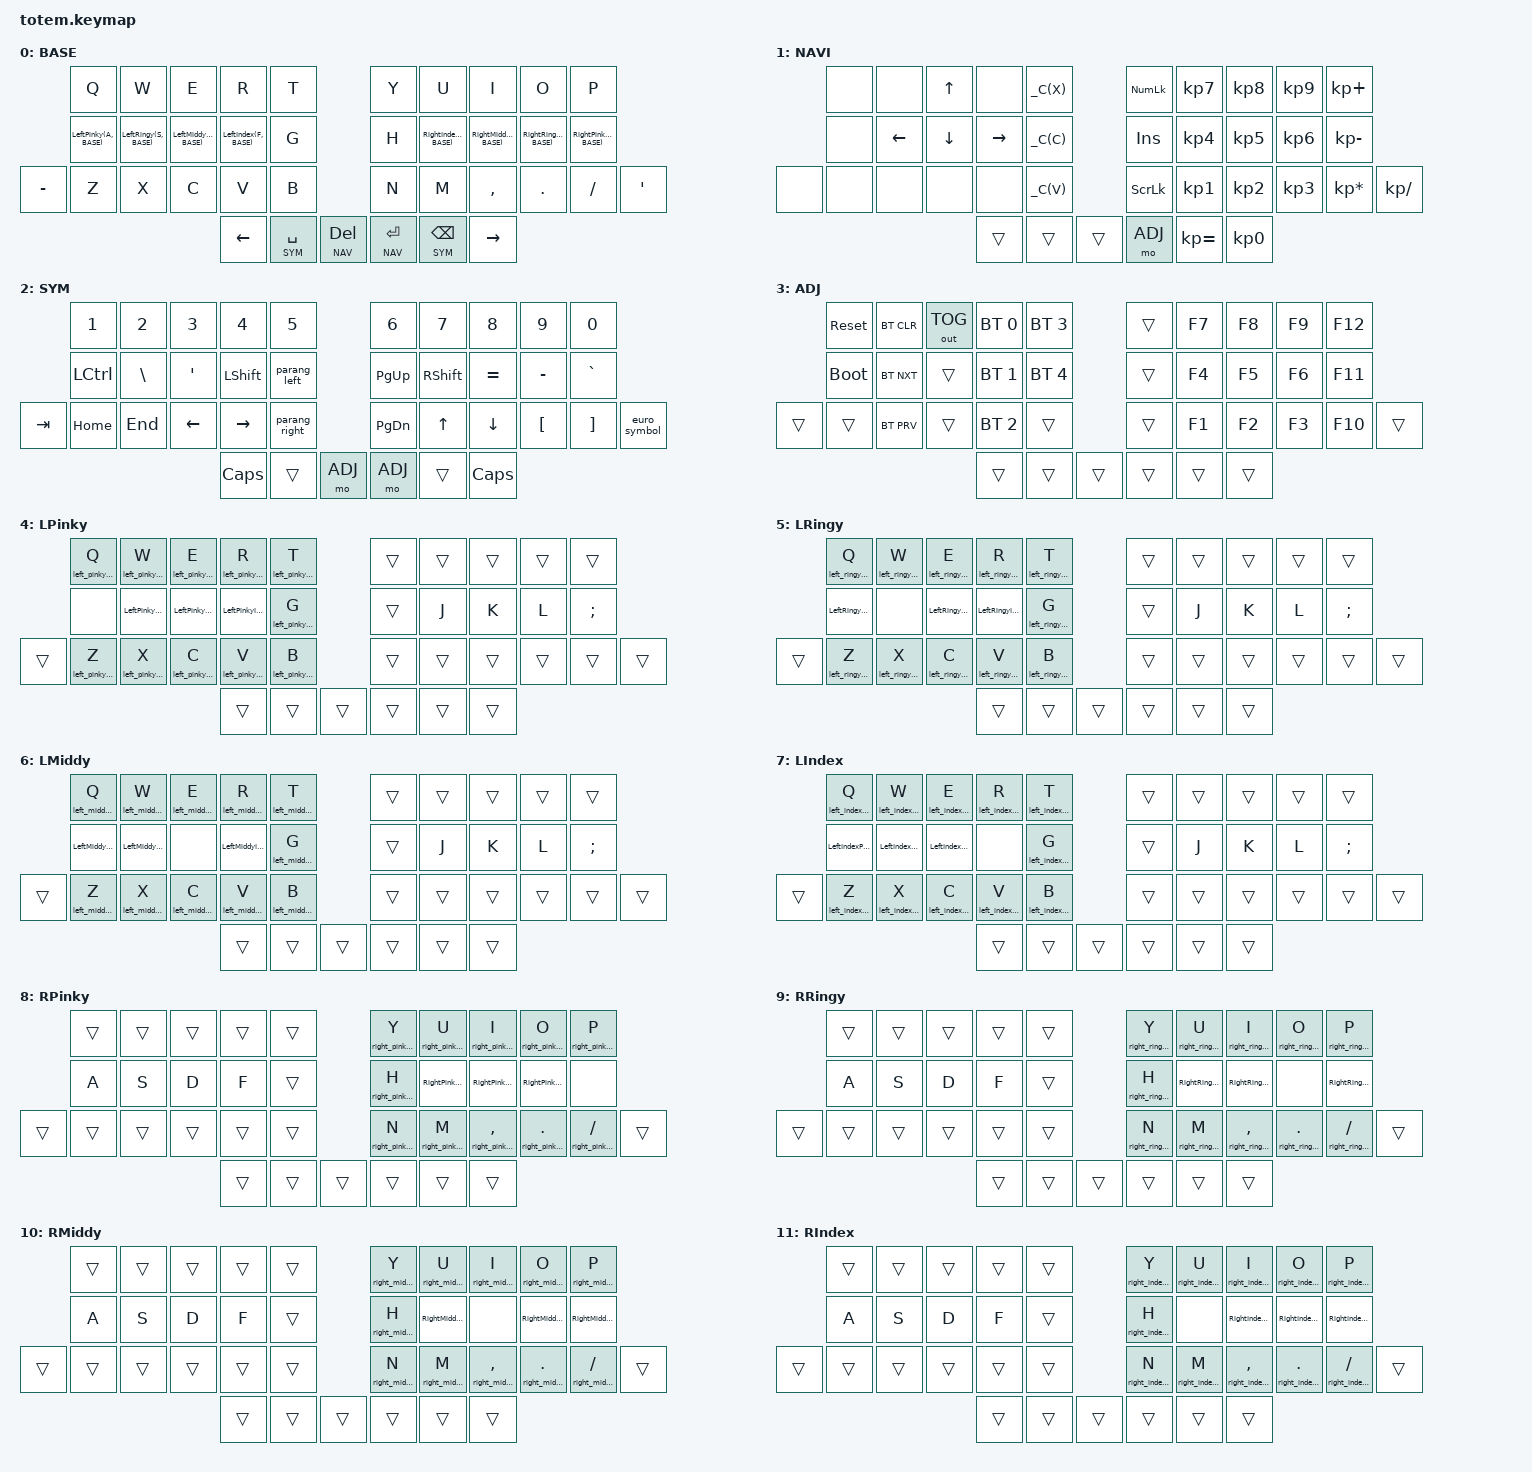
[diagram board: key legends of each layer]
//
//                                                        ▀▀▀▀▀     ▀▀▀▀▀          ▀▀█▀▀
//                                                        ▄▀▀▀▄  ▄  ▄▀▀▀▄  ▄  ▄▀▀▀▄  █  ▄▀▀▀▄
//                                                        █   █  █  █   █  █  █   █  █  █   █
//                                                         ▀▀▀   █   ▀▀▀   █   ▀▀▀   ▀   ▀▀▀
//                                                               █      ▄▄▄█▄▄▄    █   █
//                                                               ▀      █  █  █     █▄█
//                                                             ▀▀▀▀▀    █  █  █      ▀
//                                                                      ▀  ▀  ▀
//
// ▄▄▄▄▄▄▄▄▄▄▄▄▄▄▄▄▄▄▄▄▄▄▄▄▄▄▄▄▄▄▄▄▄▄▄▄▄▄▄▄▄▄▄▄▄▄▄▄▄▄▄▄▄▄▄▄▄▄▄▄▄▄▄▄▄▄▄▄▄▄▄▄▄▄▄▄▄▄▄▄▄▄▄▄▄▄▄▄▄▄▄▄▄▄▄▄▄▄▄▄▄▄▄▄▄▄▄▄▄▄▄▄▄▄▄▄▄▄▄▄▄▄▄▄▄▄▄▄▄▄▄▄▄▄▄▄▄▄▄▄▄▄▄▄▄▄▄▄▄
//
// TOTEM2 - Glove80-style bilateral home row mods with finger layers
// Based on: https://sunaku.github.io/home-row-mods.html
//

#include <behaviors.dtsi>
#include <dt-bindings/zmk/bt.h>
#include <dt-bindings/zmk/keys.h>
#include <dt-bindings/zmk/outputs.h>

// ▄▄▄▄▄▄▄▄▄▄▄▄▄▄▄▄▄▄▄▄▄▄▄▄▄▄▄▄▄▄▄▄▄▄▄▄▄▄▄▄▄▄▄▄▄▄▄▄▄▄▄▄▄▄▄▄▄▄▄▄▄▄▄▄▄▄▄▄▄▄▄▄▄▄▄▄▄▄▄▄▄▄▄▄▄▄▄▄▄▄▄▄▄▄▄▄▄▄▄▄▄▄▄▄▄▄▄▄▄▄▄▄▄▄▄▄▄▄▄▄▄▄▄▄▄▄▄▄▄▄▄▄▄▄▄▄▄▄▄▄▄▄▄▄▄▄▄▄▄
// LAYER DEFINITIONS
// ▄▄▄▄▄▄▄▄▄▄▄▄▄▄▄▄▄▄▄▄▄▄▄▄▄▄▄▄▄▄▄▄▄▄▄▄▄▄▄▄▄▄▄▄▄▄▄▄▄▄▄▄▄▄▄▄▄▄▄▄▄▄▄▄▄▄▄▄▄▄▄▄▄▄▄▄▄▄▄▄▄▄▄▄▄▄▄▄▄▄▄▄▄▄▄▄▄▄▄▄▄▄▄▄▄▄▄▄▄▄▄▄▄▄▄▄▄▄▄▄▄▄▄▄▄▄▄▄▄▄▄▄▄▄▄▄▄▄▄▄▄▄▄▄▄▄▄▄▄

#define BASE 0
#define NAV  1
#define SYM  2
#define ADJ  3
#define LAYER_LeftPinky 4
#define LAYER_LeftRingy 5
#define LAYER_LeftMiddy 6
#define LAYER_LeftIndex 7
#define LAYER_RightPinky 8
#define LAYER_RightRingy 9
#define LAYER_RightMiddy 10
#define LAYER_RightIndex 11

// ▄▄▄▄▄▄▄▄▄▄▄▄▄▄▄▄▄▄▄▄▄▄▄▄▄▄▄▄▄▄▄▄▄▄▄▄▄▄▄▄▄▄▄▄▄▄▄▄▄▄▄▄▄▄▄▄▄▄▄▄▄▄▄▄▄▄▄▄▄▄▄▄▄▄▄▄▄▄▄▄▄▄▄▄▄▄▄▄▄▄▄▄▄▄▄▄▄▄▄▄▄▄▄▄▄▄▄▄▄▄▄▄▄▄▄▄▄▄▄▄▄▄▄▄▄▄▄▄▄▄▄▄▄▄▄▄▄▄▄▄▄▄▄▄▄▄▄▄▄
// KEY POSITION DEFINITIONS (Totem 38-key layout)
// ▄▄▄▄▄▄▄▄▄▄▄▄▄▄▄▄▄▄▄▄▄▄▄▄▄▄▄▄▄▄▄▄▄▄▄▄▄▄▄▄▄▄▄▄▄▄▄▄▄▄▄▄▄▄▄▄▄▄▄▄▄▄▄▄▄▄▄▄▄▄▄▄▄▄▄▄▄▄▄▄▄▄▄▄▄▄▄▄▄▄▄▄▄▄▄▄▄▄▄▄▄▄▄▄▄▄▄▄▄▄▄▄▄▄▄▄▄▄▄▄▄▄▄▄▄▄▄▄▄▄▄▄▄▄▄▄▄▄▄▄▄▄▄▄▄▄▄▄▄
//
// Totem Layout (38 keys):
//     0   1   2   3   4       5   6   7   8   9
//    10  11  12  13  14      15  16  17  18  19
// 20 21  22  23  24  25      26  27  28  29  30  31
//            32  33  34      35  36  37
//

#define LEFT_HAND_KEYS      \
      0   1   2   3   4     \
     10  11  12  13  14     \
 20  21  22  23  24  25

#define RIGHT_HAND_KEYS     \
      5   6   7   8   9     \
     15  16  17  18  19     \
 26  27  28  29  30  31

#define THUMB_KEYS 32 33 34 35 36 37

// Home row key definitions for QWERTY
#define LEFT_PINKY_KEY   A
#define LEFT_RINGY_KEY   S
#define LEFT_MIDDY_KEY   D
#define LEFT_INDEX_KEY   F
#define RIGHT_INDEX_KEY  J
#define RIGHT_MIDDY_KEY  K
#define RIGHT_RINGY_KEY  L
#define RIGHT_PINKY_KEY  SEMI

// ▄▄▄▄▄▄▄▄▄▄▄▄▄▄▄▄▄▄▄▄▄▄▄▄▄▄▄▄▄▄▄▄▄▄▄▄▄▄▄▄▄▄▄▄▄▄▄▄▄▄▄▄▄▄▄▄▄▄▄▄▄▄▄▄▄▄▄▄▄▄▄▄▄▄▄▄▄▄▄▄▄▄▄▄▄▄▄▄▄▄▄▄▄▄▄▄▄▄▄▄▄▄▄▄▄▄▄▄▄▄▄▄▄▄▄▄▄▄▄▄▄▄▄▄▄▄▄▄▄▄▄▄▄▄▄▄▄▄▄▄▄▄▄▄▄▄▄▄▄
// OS-ADAPTIVE SHORTCUTS & MACROS
// ▄▄▄▄▄▄▄▄▄▄▄▄▄▄▄▄▄▄▄▄▄▄▄▄▄▄▄▄▄▄▄▄▄▄▄▄▄▄▄▄▄▄▄▄▄▄▄▄▄▄▄▄▄▄▄▄▄▄▄▄▄▄▄▄▄▄▄▄▄▄▄▄▄▄▄▄▄▄▄▄▄▄▄▄▄▄▄▄▄▄▄▄▄▄▄▄▄▄▄▄▄▄▄▄▄▄▄▄▄▄▄▄▄▄▄▄▄▄▄▄▄▄▄▄▄▄▄▄▄▄▄▄▄▄▄▄▄▄▄▄▄▄▄▄▄▄▄▄▄

// Uncomment for macOS:
// #define OPERATING_SYSTEM 'M'

#ifndef OPERATING_SYSTEM
#define OPERATING_SYSTEM 'W'
#endif

// Ctrl helper
#define _C(key) LC(key)

// OS-specific shortcuts
#if OPERATING_SYSTEM == 'M'
  #define _UNDO   LG(Z)
  #define _REDO   LG(LS(Z))
#else
  #define _UNDO   LC(Z)
  #define _REDO   LC(Y)
#endif

// Universal shortcuts
#define _CUT        _C(X)
#define _COPY       _C(C)
#define _PASTE      _C(V)
#define _FIND       _C(F)
#define _FIND_NEXT  _C(G)
#define _FIND_PREV  _C(LS(G))

// ▄▄▄▄▄▄▄▄▄▄▄▄▄▄▄▄▄▄▄▄▄▄▄▄▄▄▄▄▄▄▄▄▄▄▄▄▄▄▄▄▄▄▄▄▄▄▄▄▄▄▄▄▄▄▄▄▄▄▄▄▄▄▄▄▄▄▄▄▄▄▄▄▄▄▄▄▄▄▄▄▄▄▄▄▄▄▄▄▄▄▄▄▄▄▄▄▄▄▄▄▄▄▄▄▄▄▄▄▄▄▄▄▄▄▄▄▄▄▄▄▄▄▄▄▄▄▄▄▄▄▄▄▄▄▄▄▄▄▄▄▄▄▄▄▄▄▄▄▄
// HOME ROW MODS CONFIGURATION
// ▄▄▄▄▄▄▄▄▄▄▄▄▄▄▄▄▄▄▄▄▄▄▄▄▄▄▄▄▄▄▄▄▄▄▄▄▄▄▄▄▄▄▄▄▄▄▄▄▄▄▄▄▄▄▄▄▄▄▄▄▄▄▄▄▄▄▄▄▄▄▄▄▄▄▄▄▄▄▄▄▄▄▄▄▄▄▄▄▄▄▄▄▄▄▄▄▄▄▄▄▄▄▄▄▄▄▄▄▄▄▄▄▄▄▄▄▄▄▄▄▄▄▄▄▄▄▄▄▄▄▄▄▄▄▄▄▄▄▄▄▄▄▄▄▄▄▄▄▄

// Base timing (from glove80)
#ifndef TAPPING_RESOLUTION
#define TAPPING_RESOLUTION 150
#endif

// Holding times per finger
#ifndef HOMEY_HOLDING_TIME
#define HOMEY_HOLDING_TIME (TAPPING_RESOLUTION + 90)
#endif
#ifndef INDEX_HOLDING_TIME
#define INDEX_HOLDING_TIME (TAPPING_RESOLUTION - 30)  // 120ms - very fast for frequent Shift usage
#endif
#ifndef MIDDY_HOLDING_TIME
#define MIDDY_HOLDING_TIME (TAPPING_RESOLUTION + 60)
#endif
#ifndef RINGY_HOLDING_TIME
#define RINGY_HOLDING_TIME (TAPPING_RESOLUTION + 90)
#endif
#ifndef PINKY_HOLDING_TIME
#define PINKY_HOLDING_TIME (TAPPING_RESOLUTION + 130)
#endif

// Streak and repeat decay
#ifndef HOMEY_STREAK_DECAY
#define HOMEY_STREAK_DECAY TAPPING_RESOLUTION
#endif
#ifndef HOMEY_REPEAT_DECAY
#define HOMEY_REPEAT_DECAY (TAPPING_RESOLUTION + 150)
#endif
#ifndef INDEX_STREAK_DECAY
#define INDEX_STREAK_DECAY TAPPING_RESOLUTION
#endif
#ifndef INDEX_REPEAT_DECAY
#define INDEX_REPEAT_DECAY (TAPPING_RESOLUTION + 150)
#endif

// Holding types
#ifndef HOMEY_HOLDING_TYPE
#define HOMEY_HOLDING_TYPE "tap-preferred"
#endif
#ifndef INDEX_HOLDING_TYPE
#define INDEX_HOLDING_TYPE "tap-preferred"
#endif

// Chord timing (faster than single-finger)
#ifndef CHORD_HOLDING_TIME
#define CHORD_HOLDING_TIME TAPPING_RESOLUTION
#endif
#ifndef CHORD_STREAK_DECAY
#define CHORD_STREAK_DECAY HOMEY_STREAK_DECAY
#endif
#ifndef CHORD_REPEAT_DECAY
#define CHORD_REPEAT_DECAY HOMEY_REPEAT_DECAY
#endif

// Per-finger settings - LEFT HAND
#ifndef LEFT_PINKY_HOLDING_TIME
#define LEFT_PINKY_HOLDING_TIME PINKY_HOLDING_TIME
#endif
#ifndef LEFT_PINKY_STREAK_DECAY
#define LEFT_PINKY_STREAK_DECAY HOMEY_STREAK_DECAY
#endif
#ifndef LEFT_PINKY_REPEAT_DECAY
#define LEFT_PINKY_REPEAT_DECAY HOMEY_REPEAT_DECAY
#endif
#ifndef LEFT_PINKY_HOLDING_TYPE
#define LEFT_PINKY_HOLDING_TYPE HOMEY_HOLDING_TYPE
#endif

#ifndef LEFT_RINGY_HOLDING_TIME
#define LEFT_RINGY_HOLDING_TIME RINGY_HOLDING_TIME
#endif
#ifndef LEFT_RINGY_STREAK_DECAY
#define LEFT_RINGY_STREAK_DECAY HOMEY_STREAK_DECAY
#endif
#ifndef LEFT_RINGY_REPEAT_DECAY
#define LEFT_RINGY_REPEAT_DECAY HOMEY_REPEAT_DECAY
#endif
#ifndef LEFT_RINGY_HOLDING_TYPE
#define LEFT_RINGY_HOLDING_TYPE HOMEY_HOLDING_TYPE
#endif

#ifndef LEFT_MIDDY_HOLDING_TIME
#define LEFT_MIDDY_HOLDING_TIME MIDDY_HOLDING_TIME
#endif
#ifndef LEFT_MIDDY_STREAK_DECAY
#define LEFT_MIDDY_STREAK_DECAY HOMEY_STREAK_DECAY
#endif
#ifndef LEFT_MIDDY_REPEAT_DECAY
#define LEFT_MIDDY_REPEAT_DECAY HOMEY_REPEAT_DECAY
#endif
#ifndef LEFT_MIDDY_HOLDING_TYPE
#define LEFT_MIDDY_HOLDING_TYPE HOMEY_HOLDING_TYPE
#endif

#ifndef LEFT_INDEX_HOLDING_TIME
#define LEFT_INDEX_HOLDING_TIME INDEX_HOLDING_TIME
#endif
#ifndef LEFT_INDEX_STREAK_DECAY
#define LEFT_INDEX_STREAK_DECAY INDEX_STREAK_DECAY
#endif
#ifndef LEFT_INDEX_REPEAT_DECAY
#define LEFT_INDEX_REPEAT_DECAY INDEX_REPEAT_DECAY
#endif
#ifndef LEFT_INDEX_HOLDING_TYPE
#define LEFT_INDEX_HOLDING_TYPE INDEX_HOLDING_TYPE
#endif

// Per-finger settings - RIGHT HAND
#ifndef RIGHT_PINKY_HOLDING_TIME
#define RIGHT_PINKY_HOLDING_TIME PINKY_HOLDING_TIME
#endif
#ifndef RIGHT_PINKY_STREAK_DECAY
#define RIGHT_PINKY_STREAK_DECAY HOMEY_STREAK_DECAY
#endif
#ifndef RIGHT_PINKY_REPEAT_DECAY
#define RIGHT_PINKY_REPEAT_DECAY HOMEY_REPEAT_DECAY
#endif
#ifndef RIGHT_PINKY_HOLDING_TYPE
#define RIGHT_PINKY_HOLDING_TYPE HOMEY_HOLDING_TYPE
#endif

#ifndef RIGHT_RINGY_HOLDING_TIME
#define RIGHT_RINGY_HOLDING_TIME RINGY_HOLDING_TIME
#endif
#ifndef RIGHT_RINGY_STREAK_DECAY
#define RIGHT_RINGY_STREAK_DECAY HOMEY_STREAK_DECAY
#endif
#ifndef RIGHT_RINGY_REPEAT_DECAY
#define RIGHT_RINGY_REPEAT_DECAY HOMEY_REPEAT_DECAY
#endif
#ifndef RIGHT_RINGY_HOLDING_TYPE
#define RIGHT_RINGY_HOLDING_TYPE HOMEY_HOLDING_TYPE
#endif

#ifndef RIGHT_MIDDY_HOLDING_TIME
#define RIGHT_MIDDY_HOLDING_TIME MIDDY_HOLDING_TIME
#endif
#ifndef RIGHT_MIDDY_STREAK_DECAY
#define RIGHT_MIDDY_STREAK_DECAY HOMEY_STREAK_DECAY
#endif
#ifndef RIGHT_MIDDY_REPEAT_DECAY
#define RIGHT_MIDDY_REPEAT_DECAY HOMEY_REPEAT_DECAY
#endif
#ifndef RIGHT_MIDDY_HOLDING_TYPE
#define RIGHT_MIDDY_HOLDING_TYPE HOMEY_HOLDING_TYPE
#endif

#ifndef RIGHT_INDEX_HOLDING_TIME
#define RIGHT_INDEX_HOLDING_TIME INDEX_HOLDING_TIME
#endif
#ifndef RIGHT_INDEX_STREAK_DECAY
#define RIGHT_INDEX_STREAK_DECAY INDEX_STREAK_DECAY
#endif
#ifndef RIGHT_INDEX_REPEAT_DECAY
#define RIGHT_INDEX_REPEAT_DECAY INDEX_REPEAT_DECAY
#endif
#ifndef RIGHT_INDEX_HOLDING_TYPE
#define RIGHT_INDEX_HOLDING_TYPE INDEX_HOLDING_TYPE
#endif

// Chord timing per finger - LEFT HAND
#ifndef LEFT_PINKY_CHORD_HOLDING_TIME
#define LEFT_PINKY_CHORD_HOLDING_TIME CHORD_HOLDING_TIME
#endif
#ifndef LEFT_PINKY_CHORD_STREAK_DECAY
#define LEFT_PINKY_CHORD_STREAK_DECAY CHORD_STREAK_DECAY
#endif
#ifndef LEFT_PINKY_CHORD_REPEAT_DECAY
#define LEFT_PINKY_CHORD_REPEAT_DECAY CHORD_REPEAT_DECAY
#endif

#ifndef LEFT_RINGY_CHORD_HOLDING_TIME
#define LEFT_RINGY_CHORD_HOLDING_TIME CHORD_HOLDING_TIME
#endif
#ifndef LEFT_RINGY_CHORD_STREAK_DECAY
#define LEFT_RINGY_CHORD_STREAK_DECAY CHORD_STREAK_DECAY
#endif
#ifndef LEFT_RINGY_CHORD_REPEAT_DECAY
#define LEFT_RINGY_CHORD_REPEAT_DECAY CHORD_REPEAT_DECAY
#endif

#ifndef LEFT_MIDDY_CHORD_HOLDING_TIME
#define LEFT_MIDDY_CHORD_HOLDING_TIME CHORD_HOLDING_TIME
#endif
#ifndef LEFT_MIDDY_CHORD_STREAK_DECAY
#define LEFT_MIDDY_CHORD_STREAK_DECAY CHORD_STREAK_DECAY
#endif
#ifndef LEFT_MIDDY_CHORD_REPEAT_DECAY
#define LEFT_MIDDY_CHORD_REPEAT_DECAY CHORD_REPEAT_DECAY
#endif

#ifndef LEFT_INDEX_CHORD_HOLDING_TIME
#define LEFT_INDEX_CHORD_HOLDING_TIME CHORD_HOLDING_TIME
#endif
#ifndef LEFT_INDEX_CHORD_STREAK_DECAY
#define LEFT_INDEX_CHORD_STREAK_DECAY CHORD_STREAK_DECAY
#endif
#ifndef LEFT_INDEX_CHORD_REPEAT_DECAY
#define LEFT_INDEX_CHORD_REPEAT_DECAY CHORD_REPEAT_DECAY
#endif

// Chord timing per finger - RIGHT HAND
#ifndef RIGHT_PINKY_CHORD_HOLDING_TIME
#define RIGHT_PINKY_CHORD_HOLDING_TIME CHORD_HOLDING_TIME
#endif
#ifndef RIGHT_PINKY_CHORD_STREAK_DECAY
#define RIGHT_PINKY_CHORD_STREAK_DECAY CHORD_STREAK_DECAY
#endif
#ifndef RIGHT_PINKY_CHORD_REPEAT_DECAY
#define RIGHT_PINKY_CHORD_REPEAT_DECAY CHORD_REPEAT_DECAY
#endif

#ifndef RIGHT_RINGY_CHORD_HOLDING_TIME
#define RIGHT_RINGY_CHORD_HOLDING_TIME CHORD_HOLDING_TIME
#endif
#ifndef RIGHT_RINGY_CHORD_STREAK_DECAY
#define RIGHT_RINGY_CHORD_STREAK_DECAY CHORD_STREAK_DECAY
#endif
#ifndef RIGHT_RINGY_CHORD_REPEAT_DECAY
#define RIGHT_RINGY_CHORD_REPEAT_DECAY CHORD_REPEAT_DECAY
#endif

#ifndef RIGHT_MIDDY_CHORD_HOLDING_TIME
#define RIGHT_MIDDY_CHORD_HOLDING_TIME CHORD_HOLDING_TIME
#endif
#ifndef RIGHT_MIDDY_CHORD_STREAK_DECAY
#define RIGHT_MIDDY_CHORD_STREAK_DECAY CHORD_STREAK_DECAY
#endif
#ifndef RIGHT_MIDDY_CHORD_REPEAT_DECAY
#define RIGHT_MIDDY_CHORD_REPEAT_DECAY CHORD_REPEAT_DECAY
#endif

#ifndef RIGHT_INDEX_CHORD_HOLDING_TIME
#define RIGHT_INDEX_CHORD_HOLDING_TIME CHORD_HOLDING_TIME
#endif
#ifndef RIGHT_INDEX_CHORD_STREAK_DECAY
#define RIGHT_INDEX_CHORD_STREAK_DECAY CHORD_STREAK_DECAY
#endif
#ifndef RIGHT_INDEX_CHORD_REPEAT_DECAY
#define RIGHT_INDEX_CHORD_REPEAT_DECAY CHORD_REPEAT_DECAY
#endif

// Modifier assignments (GACS order)
#ifndef PINKY_FINGER_MOD
#define PINKY_FINGER_MOD LGUI
#endif
#ifndef RINGY_FINGER_MOD
#define RINGY_FINGER_MOD LALT
#endif
#ifndef MIDDY_FINGER_MOD
#define MIDDY_FINGER_MOD LCTL
#endif
#ifndef INDEX_FINGER_MOD
#define INDEX_FINGER_MOD LSFT
#endif

#ifndef LEFT_PINKY_MOD
#define LEFT_PINKY_MOD PINKY_FINGER_MOD
#endif
#ifndef RIGHT_PINKY_MOD
#define RIGHT_PINKY_MOD PINKY_FINGER_MOD
#endif
#ifndef LEFT_RINGY_MOD
#define LEFT_RINGY_MOD RINGY_FINGER_MOD
#endif
#ifndef RIGHT_RINGY_MOD
#define RIGHT_RINGY_MOD RINGY_FINGER_MOD
#endif
#ifndef LEFT_MIDDY_MOD
#define LEFT_MIDDY_MOD MIDDY_FINGER_MOD
#endif
#ifndef RIGHT_MIDDY_MOD
#define RIGHT_MIDDY_MOD MIDDY_FINGER_MOD
#endif
#ifndef LEFT_INDEX_MOD
#define LEFT_INDEX_MOD INDEX_FINGER_MOD
#endif
#ifndef RIGHT_INDEX_MOD
#define RIGHT_INDEX_MOD INDEX_FINGER_MOD
#endif

/ {
    behaviors {

// ▄▄▄▄▄▄▄▄▄▄▄▄▄▄▄▄▄▄▄▄▄▄▄▄▄▄▄▄▄▄▄▄▄▄▄▄▄▄▄▄▄▄▄▄▄▄▄▄▄▄▄▄▄▄▄▄▄▄▄▄▄▄▄▄▄▄▄▄▄▄▄▄▄▄▄▄▄▄▄▄▄▄▄▄▄▄▄▄▄▄▄▄▄▄▄▄▄▄▄▄▄▄▄▄▄▄▄▄▄▄▄▄▄▄▄▄▄▄▄▄▄▄▄▄▄▄▄▄▄▄▄▄▄▄▄▄▄▄▄▄▄▄▄▄▄▄▄▄▄
// TEXT SELECTION BEHAVIORS
// ▄▄▄▄▄▄▄▄▄▄▄▄▄▄▄▄▄▄▄▄▄▄▄▄▄▄▄▄▄▄▄▄▄▄▄▄▄▄▄▄▄▄▄▄▄▄▄▄▄▄▄▄▄▄▄▄▄▄▄▄▄▄▄▄▄▄▄▄▄▄▄▄▄▄▄▄▄▄▄▄▄▄▄▄▄▄▄▄▄▄▄▄▄▄▄▄▄▄▄▄▄▄▄▄▄▄▄▄▄▄▄▄▄▄▄▄▄▄▄▄▄▄▄▄▄▄▄▄▄▄▄▄▄▄▄▄▄▄▄▄▄▄▄▄▄▄▄▄▄

        // Select all macro
        #define select_all kp _C(A)

        // Select word (with direction based on shift)
        select_word_right: select_word_right {
            compatible = "zmk,behavior-macro";
            #binding-cells = <0>;
            wait-ms = <10>;
            tap-ms = <10>;
            bindings = <&kp LC(RIGHT) &kp LS(LC(RIGHT))>;
        };
        select_word_left: select_word_left {
            compatible = "zmk,behavior-macro";
            #binding-cells = <0>;
            wait-ms = <10>;
            tap-ms = <10>;
            bindings = <&kp LC(LEFT) &kp LS(LC(LEFT))>;
        };
        select_word: select_word {
            compatible = "zmk,behavior-mod-morph";
            #binding-cells = <0>;
            bindings = <&select_word_right>, <&select_word_left>;
            mods = <(MOD_LSFT|MOD_RSFT)>;
        };

        // Extend word (extend selection by one word)
        extend_word_right: extend_word_right {
            compatible = "zmk,behavior-macro";
            #binding-cells = <0>;
            wait-ms = <10>;
            tap-ms = <10>;
            bindings = <&kp LS(LC(RIGHT))>;
        };
        extend_word_left: extend_word_left {
            compatible = "zmk,behavior-macro";
            #binding-cells = <0>;
            wait-ms = <10>;
            tap-ms = <10>;
            bindings = <&kp LS(LC(LEFT))>;
        };
        extend_word: extend_word {
            compatible = "zmk,behavior-mod-morph";
            #binding-cells = <0>;
            bindings = <&extend_word_right>, <&extend_word_left>;
            mods = <(MOD_LSFT|MOD_RSFT)>;
        };

        // Parenthesis/angle bracket morphs
        parang_left: parang_left {
            compatible = "zmk,behavior-mod-morph";
            label = "PARANG_LEFT";
            #binding-cells = <0>;
            bindings = <&kp LPAR>, <&kp LT>;
            mods = <(MOD_LSFT|MOD_RSFT)>;
        };
        parang_right: parang_right {
            compatible = "zmk,behavior-mod-morph";
            label = "PARANG_RIGHT";
            #binding-cells = <0>;
            bindings = <&kp RPAR>, <&kp GT>;
            mods = <(MOD_LSFT|MOD_RSFT)>;
        };

        // Euro symbol macro (Windows: Alt+0128)
        euro_symbol: euro_symbol {
            compatible = "zmk,behavior-macro";
            #binding-cells = <0>;
            wait-ms = <10>;
            tap-ms = <10>;
            bindings = <&macro_press &kp LALT>
                     , <&macro_tap &kp KP_N0 &kp KP_N1 &kp KP_N2 &kp KP_N8>
                     , <&macro_release &kp LALT>;
        };

// ▄▄▄▄▄▄▄▄▄▄▄▄▄▄▄▄▄▄▄▄▄▄▄▄▄▄▄▄▄▄▄▄▄▄▄▄▄▄▄▄▄▄▄▄▄▄▄▄▄▄▄▄▄▄▄▄▄▄▄▄▄▄▄▄▄▄▄▄▄▄▄▄▄▄▄▄▄▄▄▄▄▄▄▄▄▄▄▄▄▄▄▄▄▄▄▄▄▄▄▄▄▄▄▄▄▄▄▄▄▄▄▄▄▄▄▄▄▄▄▄▄▄▄▄▄▄▄▄▄▄▄▄▄▄▄▄▄▄▄▄▄▄▄▄▄▄▄▄▄
// THUMB LAYER-TAP BEHAVIORS WITH AUTO-REPEAT
// ▄▄▄▄▄▄▄▄▄▄▄▄▄▄▄▄▄▄▄▄▄▄▄▄▄▄▄▄▄▄▄▄▄▄▄▄▄▄▄▄▄▄▄▄▄▄▄▄▄▄▄▄▄▄▄▄▄▄▄▄▄▄▄▄▄▄▄▄▄▄▄▄▄▄▄▄▄▄▄▄▄▄▄▄▄▄▄▄▄▄▄▄▄▄▄▄▄▄▄▄▄▄▄▄▄▄▄▄▄▄▄▄▄▄▄▄▄▄▄▄▄▄▄▄▄▄▄▄▄▄▄▄▄▄▄▄▄▄▄▄▄▄▄▄▄▄▄▄▄

        // Thumb layer-tap with auto-repeat: tap for key, hold for layer, tap-tap-hold for auto-repeat
        lt_space_sym: lt_space_sym {
            compatible = "zmk,behavior-hold-tap";
            label = "LT_SPACE_SYM";
            #binding-cells = <2>;
            flavor = "balanced";
            tapping-term-ms = <200>;
            quick-tap-ms = <200>;  // Enable "tap then hold" for auto-repeat
            bindings = <&mo>, <&kp>;
        };

        lt_bspc_sym: lt_bspc_sym {
            compatible = "zmk,behavior-hold-tap";
            label = "LT_BSPC_SYM";
            #binding-cells = <2>;
            flavor = "balanced";
            tapping-term-ms = <200>;
            quick-tap-ms = <200>;
            bindings = <&mo>, <&kp>;
        };

        lt_del_nav: lt_del_nav {
            compatible = "zmk,behavior-hold-tap";
            label = "LT_DEL_NAV";
            #binding-cells = <2>;
            flavor = "balanced";
            tapping-term-ms = <200>;
            quick-tap-ms = <200>;
            bindings = <&mo>, <&kp>;
        };

        lt_ret_nav: lt_ret_nav {
            compatible = "zmk,behavior-hold-tap";
            label = "LT_RET_NAV";
            #binding-cells = <2>;
            flavor = "balanced";
            tapping-term-ms = <200>;
            quick-tap-ms = <200>;
            bindings = <&mo>, <&kp>;
        };

// ▄▄▄▄▄▄▄▄▄▄▄▄▄▄▄▄▄▄▄▄▄▄▄▄▄▄▄▄▄▄▄▄▄▄▄▄▄▄▄▄▄▄▄▄▄▄▄▄▄▄▄▄▄▄▄▄▄▄▄▄▄▄▄▄▄▄▄▄▄▄▄▄▄▄▄▄▄▄▄▄▄▄▄▄▄▄▄▄▄▄▄▄▄▄▄▄▄▄▄▄▄▄▄▄▄▄▄▄▄▄▄▄▄▄▄▄▄▄▄▄▄▄▄▄▄▄▄▄▄▄▄▄▄▄▄▄▄▄▄▄▄▄▄▄▄▄▄▄▄
// LEFT PINKY BEHAVIORS
// ▄▄▄▄▄▄▄▄▄▄▄▄▄▄▄▄▄▄▄▄▄▄▄▄▄▄▄▄▄▄▄▄▄▄▄▄▄▄▄▄▄▄▄▄▄▄▄▄▄▄▄▄▄▄▄▄▄▄▄▄▄▄▄▄▄▄▄▄▄▄▄▄▄▄▄▄▄▄▄▄▄▄▄▄▄▄▄▄▄▄▄▄▄▄▄▄▄▄▄▄▄▄▄▄▄▄▄▄▄▄▄▄▄▄▄▄▄▄▄▄▄▄▄▄▄▄▄▄▄▄▄▄▄▄▄▄▄▄▄▄▄▄▄▄▄▄▄▄▄

        left_pinky: homey_left_pinky {
            compatible = "zmk,behavior-hold-tap";
            flavor = LEFT_PINKY_HOLDING_TYPE;
            hold-trigger-key-positions = <RIGHT_HAND_KEYS THUMB_KEYS>;
            hold-trigger-on-release;
            tapping-term-ms = <LEFT_PINKY_HOLDING_TIME>;
            quick-tap-ms = <LEFT_PINKY_REPEAT_DECAY>;
            require-prior-idle-ms = <LEFT_PINKY_STREAK_DECAY>;
            #binding-cells = <2>;
            bindings = <&kp>, <&kp>;
        };

        left_pinky_bilateral: homey_left_pinky_bilateral {
            compatible = "zmk,behavior-hold-tap";
            flavor = LEFT_PINKY_HOLDING_TYPE;
            hold-trigger-key-positions = <RIGHT_HAND_KEYS THUMB_KEYS>;
            hold-trigger-on-release;
            tapping-term-ms = <LEFT_PINKY_HOLDING_TIME>;
            quick-tap-ms = <LEFT_PINKY_REPEAT_DECAY>;
            require-prior-idle-ms = <LEFT_PINKY_STREAK_DECAY>;
            #binding-cells = <2>;
            bindings = <&left_pinky_hold>, <&kp>;
        };

        left_pinky_hold: homey_left_pinky_hold {
            compatible = "zmk,behavior-macro-one-param";
            wait-ms = <0>;
            tap-ms = <0>;
            #binding-cells = <1>;
            bindings
                = <&macro_param_1to1>
                , <&macro_press &kp MACRO_PLACEHOLDER>
                , <&macro_press &mo LAYER_LeftPinky>
                , <&macro_pause_for_release>
                , <&macro_param_1to1>
                , <&macro_release &kp MACRO_PLACEHOLDER>
                , <&macro_release &mo LAYER_LeftPinky>
                ;
        };

        left_pinky_tap: homey_left_pinky_tap {
            compatible = "zmk,behavior-macro-one-param";
            wait-ms = <0>;
            tap-ms = <0>;
            #binding-cells = <1>;
            bindings
                = <&macro_release
                    &kp LSFT &kp RSFT
                    &kp LALT &kp RALT
                    &kp LCTL &kp RCTL
                    &kp LGUI &kp RGUI>
                , <&macro_tap &kp LEFT_PINKY_KEY>
                , <&macro_param_1to1>
                , <&macro_tap &kp MACRO_PLACEHOLDER>
                ;
        };

        #define LeftPinky(key, layer_index) LeftPinky_unroll(layer_index) (key)
        #define LeftPinky_unroll(layer_index) LeftPinky_concat(LeftPinky_layer, layer_index)
        #define LeftPinky_concat(prefix, layer_index) prefix ## layer_index
        #define LeftPinky_layer0(key) left_pinky_bilateral LEFT_PINKY_MOD key
        #define LeftPinky_layer1(key) left_pinky LEFT_PINKY_MOD key
        #define LeftPinky_layer2(key) left_pinky LEFT_PINKY_MOD key
        #define LeftPinky_layer3(key) left_pinky LEFT_PINKY_MOD key

// ▄▄▄▄▄▄▄▄▄▄▄▄▄▄▄▄▄▄▄▄▄▄▄▄▄▄▄▄▄▄▄▄▄▄▄▄▄▄▄▄▄▄▄▄▄▄▄▄▄▄▄▄▄▄▄▄▄▄▄▄▄▄▄▄▄▄▄▄▄▄▄▄▄▄▄▄▄▄▄▄▄▄▄▄▄▄▄▄▄▄▄▄▄▄▄▄▄▄▄▄▄▄▄▄▄▄▄▄▄▄▄▄▄▄▄▄▄▄▄▄▄▄▄▄▄▄▄▄▄▄▄▄▄▄▄▄▄▄▄▄▄▄▄▄▄▄▄▄▄
// LEFT RINGY BEHAVIORS
// ▄▄▄▄▄▄▄▄▄▄▄▄▄▄▄▄▄▄▄▄▄▄▄▄▄▄▄▄▄▄▄▄▄▄▄▄▄▄▄▄▄▄▄▄▄▄▄▄▄▄▄▄▄▄▄▄▄▄▄▄▄▄▄▄▄▄▄▄▄▄▄▄▄▄▄▄▄▄▄▄▄▄▄▄▄▄▄▄▄▄▄▄▄▄▄▄▄▄▄▄▄▄▄▄▄▄▄▄▄▄▄▄▄▄▄▄▄▄▄▄▄▄▄▄▄▄▄▄▄▄▄▄▄▄▄▄▄▄▄▄▄▄▄▄▄▄▄▄▄

        left_ringy: homey_left_ringy {
            compatible = "zmk,behavior-hold-tap";
            flavor = LEFT_RINGY_HOLDING_TYPE;
            hold-trigger-key-positions = <RIGHT_HAND_KEYS THUMB_KEYS>;
            hold-trigger-on-release;
            tapping-term-ms = <LEFT_RINGY_HOLDING_TIME>;
            quick-tap-ms = <LEFT_RINGY_REPEAT_DECAY>;
            require-prior-idle-ms = <LEFT_RINGY_STREAK_DECAY>;
            #binding-cells = <2>;
            bindings = <&kp>, <&kp>;
        };

        left_ringy_bilateral: homey_left_ringy_bilateral {
            compatible = "zmk,behavior-hold-tap";
            flavor = LEFT_RINGY_HOLDING_TYPE;
            hold-trigger-key-positions = <RIGHT_HAND_KEYS THUMB_KEYS>;
            hold-trigger-on-release;
            tapping-term-ms = <LEFT_RINGY_HOLDING_TIME>;
            quick-tap-ms = <LEFT_RINGY_REPEAT_DECAY>;
            require-prior-idle-ms = <LEFT_RINGY_STREAK_DECAY>;
            #binding-cells = <2>;
            bindings = <&left_ringy_hold>, <&kp>;
        };

        left_ringy_hold: homey_left_ringy_hold {
            compatible = "zmk,behavior-macro-one-param";
            wait-ms = <0>;
            tap-ms = <0>;
            #binding-cells = <1>;
            bindings
                = <&macro_param_1to1>
                , <&macro_press &kp MACRO_PLACEHOLDER>
                , <&macro_press &mo LAYER_LeftRingy>
                , <&macro_pause_for_release>
                , <&macro_param_1to1>
                , <&macro_release &kp MACRO_PLACEHOLDER>
                , <&macro_release &mo LAYER_LeftRingy>
                ;
        };

        left_ringy_tap: homey_left_ringy_tap {
            compatible = "zmk,behavior-macro-one-param";
            wait-ms = <0>;
            tap-ms = <0>;
            #binding-cells = <1>;
            bindings
                = <&macro_release
                    &kp LSFT &kp RSFT
                    &kp LALT &kp RALT
                    &kp LCTL &kp RCTL
                    &kp LGUI &kp RGUI>
                , <&macro_tap &kp LEFT_RINGY_KEY>
                , <&macro_param_1to1>
                , <&macro_tap &kp MACRO_PLACEHOLDER>
                ;
        };

        #define LeftRingy(key, layer_index) LeftRingy_unroll(layer_index) (key)
        #define LeftRingy_unroll(layer_index) LeftRingy_concat(LeftRingy_layer, layer_index)
        #define LeftRingy_concat(prefix, layer_index) prefix ## layer_index
        #define LeftRingy_layer0(key) left_ringy_bilateral LEFT_RINGY_MOD key
        #define LeftRingy_layer1(key) left_ringy LEFT_RINGY_MOD key
        #define LeftRingy_layer2(key) left_ringy LEFT_RINGY_MOD key
        #define LeftRingy_layer3(key) left_ringy LEFT_RINGY_MOD key

// ▄▄▄▄▄▄▄▄▄▄▄▄▄▄▄▄▄▄▄▄▄▄▄▄▄▄▄▄▄▄▄▄▄▄▄▄▄▄▄▄▄▄▄▄▄▄▄▄▄▄▄▄▄▄▄▄▄▄▄▄▄▄▄▄▄▄▄▄▄▄▄▄▄▄▄▄▄▄▄▄▄▄▄▄▄▄▄▄▄▄▄▄▄▄▄▄▄▄▄▄▄▄▄▄▄▄▄▄▄▄▄▄▄▄▄▄▄▄▄▄▄▄▄▄▄▄▄▄▄▄▄▄▄▄▄▄▄▄▄▄▄▄▄▄▄▄▄▄▄
// LEFT MIDDY BEHAVIORS
// ▄▄▄▄▄▄▄▄▄▄▄▄▄▄▄▄▄▄▄▄▄▄▄▄▄▄▄▄▄▄▄▄▄▄▄▄▄▄▄▄▄▄▄▄▄▄▄▄▄▄▄▄▄▄▄▄▄▄▄▄▄▄▄▄▄▄▄▄▄▄▄▄▄▄▄▄▄▄▄▄▄▄▄▄▄▄▄▄▄▄▄▄▄▄▄▄▄▄▄▄▄▄▄▄▄▄▄▄▄▄▄▄▄▄▄▄▄▄▄▄▄▄▄▄▄▄▄▄▄▄▄▄▄▄▄▄▄▄▄▄▄▄▄▄▄▄▄▄▄

        left_middy: homey_left_middy {
            compatible = "zmk,behavior-hold-tap";
            flavor = LEFT_MIDDY_HOLDING_TYPE;
            hold-trigger-key-positions = <RIGHT_HAND_KEYS THUMB_KEYS>;
            hold-trigger-on-release;
            tapping-term-ms = <LEFT_MIDDY_HOLDING_TIME>;
            quick-tap-ms = <LEFT_MIDDY_REPEAT_DECAY>;
            require-prior-idle-ms = <LEFT_MIDDY_STREAK_DECAY>;
            #binding-cells = <2>;
            bindings = <&kp>, <&kp>;
        };

        left_middy_bilateral: homey_left_middy_bilateral {
            compatible = "zmk,behavior-hold-tap";
            flavor = LEFT_MIDDY_HOLDING_TYPE;
            hold-trigger-key-positions = <RIGHT_HAND_KEYS THUMB_KEYS>;
            hold-trigger-on-release;
            tapping-term-ms = <LEFT_MIDDY_HOLDING_TIME>;
            quick-tap-ms = <LEFT_MIDDY_REPEAT_DECAY>;
            require-prior-idle-ms = <LEFT_MIDDY_STREAK_DECAY>;
            #binding-cells = <2>;
            bindings = <&left_middy_hold>, <&kp>;
        };

        left_middy_hold: homey_left_middy_hold {
            compatible = "zmk,behavior-macro-one-param";
            wait-ms = <0>;
            tap-ms = <0>;
            #binding-cells = <1>;
            bindings
                = <&macro_param_1to1>
                , <&macro_press &kp MACRO_PLACEHOLDER>
                , <&macro_press &mo LAYER_LeftMiddy>
                , <&macro_pause_for_release>
                , <&macro_param_1to1>
                , <&macro_release &kp MACRO_PLACEHOLDER>
                , <&macro_release &mo LAYER_LeftMiddy>
                ;
        };

        left_middy_tap: homey_left_middy_tap {
            compatible = "zmk,behavior-macro-one-param";
            wait-ms = <0>;
            tap-ms = <0>;
            #binding-cells = <1>;
            bindings
                = <&macro_release
                    &kp LSFT &kp RSFT
                    &kp LALT &kp RALT
                    &kp LCTL &kp RCTL
                    &kp LGUI &kp RGUI>
                , <&macro_tap &kp LEFT_MIDDY_KEY>
                , <&macro_param_1to1>
                , <&macro_tap &kp MACRO_PLACEHOLDER>
                ;
        };

        #define LeftMiddy(key, layer_index) LeftMiddy_unroll(layer_index) (key)
        #define LeftMiddy_unroll(layer_index) LeftMiddy_concat(LeftMiddy_layer, layer_index)
        #define LeftMiddy_concat(prefix, layer_index) prefix ## layer_index
        #define LeftMiddy_layer0(key) left_middy_bilateral LEFT_MIDDY_MOD key
        #define LeftMiddy_layer1(key) left_middy LEFT_MIDDY_MOD key
        #define LeftMiddy_layer2(key) left_middy LEFT_MIDDY_MOD key
        #define LeftMiddy_layer3(key) left_middy LEFT_MIDDY_MOD key

// ▄▄▄▄▄▄▄▄▄▄▄▄▄▄▄▄▄▄▄▄▄▄▄▄▄▄▄▄▄▄▄▄▄▄▄▄▄▄▄▄▄▄▄▄▄▄▄▄▄▄▄▄▄▄▄▄▄▄▄▄▄▄▄▄▄▄▄▄▄▄▄▄▄▄▄▄▄▄▄▄▄▄▄▄▄▄▄▄▄▄▄▄▄▄▄▄▄▄▄▄▄▄▄▄▄▄▄▄▄▄▄▄▄▄▄▄▄▄▄▄▄▄▄▄▄▄▄▄▄▄▄▄▄▄▄▄▄▄▄▄▄▄▄▄▄▄▄▄▄
// LEFT INDEX BEHAVIORS
// ▄▄▄▄▄▄▄▄▄▄▄▄▄▄▄▄▄▄▄▄▄▄▄▄▄▄▄▄▄▄▄▄▄▄▄▄▄▄▄▄▄▄▄▄▄▄▄▄▄▄▄▄▄▄▄▄▄▄▄▄▄▄▄▄▄▄▄▄▄▄▄▄▄▄▄▄▄▄▄▄▄▄▄▄▄▄▄▄▄▄▄▄▄▄▄▄▄▄▄▄▄▄▄▄▄▄▄▄▄▄▄▄▄▄▄▄▄▄▄▄▄▄▄▄▄▄▄▄▄▄▄▄▄▄▄▄▄▄▄▄▄▄▄▄▄▄▄▄▄

        left_index: homey_left_index {
            compatible = "zmk,behavior-hold-tap";
            flavor = LEFT_INDEX_HOLDING_TYPE;
            hold-trigger-key-positions = <RIGHT_HAND_KEYS THUMB_KEYS>;
            hold-trigger-on-release;
            tapping-term-ms = <LEFT_INDEX_HOLDING_TIME>;
            quick-tap-ms = <LEFT_INDEX_REPEAT_DECAY>;
            require-prior-idle-ms = <LEFT_INDEX_STREAK_DECAY>;
            #binding-cells = <2>;
            bindings = <&kp>, <&kp>;
        };

        left_index_bilateral: homey_left_index_bilateral {
            compatible = "zmk,behavior-hold-tap";
            flavor = LEFT_INDEX_HOLDING_TYPE;
            hold-trigger-key-positions = <RIGHT_HAND_KEYS THUMB_KEYS>;
            hold-trigger-on-release;
            tapping-term-ms = <LEFT_INDEX_HOLDING_TIME>;
            quick-tap-ms = <LEFT_INDEX_REPEAT_DECAY>;
            require-prior-idle-ms = <LEFT_INDEX_STREAK_DECAY>;
            #binding-cells = <2>;
            bindings = <&left_index_hold>, <&kp>;
        };

        left_index_hold: homey_left_index_hold {
            compatible = "zmk,behavior-macro-one-param";
            wait-ms = <0>;
            tap-ms = <0>;
            #binding-cells = <1>;
            bindings
                = <&macro_param_1to1>
                , <&macro_press &kp MACRO_PLACEHOLDER>
                , <&macro_press &mo LAYER_LeftIndex>
                , <&macro_pause_for_release>
                , <&macro_param_1to1>
                , <&macro_release &kp MACRO_PLACEHOLDER>
                , <&macro_release &mo LAYER_LeftIndex>
                ;
        };

        left_index_tap: homey_left_index_tap {
            compatible = "zmk,behavior-macro-one-param";
            wait-ms = <0>;
            tap-ms = <0>;
            #binding-cells = <1>;
            bindings
                = <&macro_release
                    &kp LSFT &kp RSFT
                    &kp LALT &kp RALT
                    &kp LCTL &kp RCTL
                    &kp LGUI &kp RGUI>
                , <&macro_tap &kp LEFT_INDEX_KEY>
                , <&macro_param_1to1>
                , <&macro_tap &kp MACRO_PLACEHOLDER>
                ;
        };

        #define LeftIndex(key, layer_index) LeftIndex_unroll(layer_index) (key)
        #define LeftIndex_unroll(layer_index) LeftIndex_concat(LeftIndex_layer, layer_index)
        #define LeftIndex_concat(prefix, layer_index) prefix ## layer_index
        #define LeftIndex_layer0(key) left_index_bilateral LEFT_INDEX_MOD key
        #define LeftIndex_layer1(key) left_index LEFT_INDEX_MOD key
        #define LeftIndex_layer2(key) left_index LEFT_INDEX_MOD key
        #define LeftIndex_layer3(key) left_index LEFT_INDEX_MOD key

// ▄▄▄▄▄▄▄▄▄▄▄▄▄▄▄▄▄▄▄▄▄▄▄▄▄▄▄▄▄▄▄▄▄▄▄▄▄▄▄▄▄▄▄▄▄▄▄▄▄▄▄▄▄▄▄▄▄▄▄▄▄▄▄▄▄▄▄▄▄▄▄▄▄▄▄▄▄▄▄▄▄▄▄▄▄▄▄▄▄▄▄▄▄▄▄▄▄▄▄▄▄▄▄▄▄▄▄▄▄▄▄▄▄▄▄▄▄▄▄▄▄▄▄▄▄▄▄▄▄▄▄▄▄▄▄▄▄▄▄▄▄▄▄▄▄▄▄▄▄
// RIGHT INDEX BEHAVIORS
// ▄▄▄▄▄▄▄▄▄▄▄▄▄▄▄▄▄▄▄▄▄▄▄▄▄▄▄▄▄▄▄▄▄▄▄▄▄▄▄▄▄▄▄▄▄▄▄▄▄▄▄▄▄▄▄▄▄▄▄▄▄▄▄▄▄▄▄▄▄▄▄▄▄▄▄▄▄▄▄▄▄▄▄▄▄▄▄▄▄▄▄▄▄▄▄▄▄▄▄▄▄▄▄▄▄▄▄▄▄▄▄▄▄▄▄▄▄▄▄▄▄▄▄▄▄▄▄▄▄▄▄▄▄▄▄▄▄▄▄▄▄▄▄▄▄▄▄▄▄

        right_index: homey_right_index {
            compatible = "zmk,behavior-hold-tap";
            flavor = RIGHT_INDEX_HOLDING_TYPE;
            hold-trigger-key-positions = <LEFT_HAND_KEYS THUMB_KEYS>;
            hold-trigger-on-release;
            tapping-term-ms = <RIGHT_INDEX_HOLDING_TIME>;
            quick-tap-ms = <RIGHT_INDEX_REPEAT_DECAY>;
            require-prior-idle-ms = <RIGHT_INDEX_STREAK_DECAY>;
            #binding-cells = <2>;
            bindings = <&kp>, <&kp>;
        };

        right_index_bilateral: homey_right_index_bilateral {
            compatible = "zmk,behavior-hold-tap";
            flavor = RIGHT_INDEX_HOLDING_TYPE;
            hold-trigger-key-positions = <LEFT_HAND_KEYS THUMB_KEYS>;
            hold-trigger-on-release;
            tapping-term-ms = <RIGHT_INDEX_HOLDING_TIME>;
            quick-tap-ms = <RIGHT_INDEX_REPEAT_DECAY>;
            require-prior-idle-ms = <RIGHT_INDEX_STREAK_DECAY>;
            #binding-cells = <2>;
            bindings = <&right_index_hold>, <&kp>;
        };

        right_index_hold: homey_right_index_hold {
            compatible = "zmk,behavior-macro-one-param";
            wait-ms = <0>;
            tap-ms = <0>;
            #binding-cells = <1>;
            bindings
                = <&macro_param_1to1>
                , <&macro_press &kp MACRO_PLACEHOLDER>
                , <&macro_press &mo LAYER_RightIndex>
                , <&macro_pause_for_release>
                , <&macro_param_1to1>
                , <&macro_release &kp MACRO_PLACEHOLDER>
                , <&macro_release &mo LAYER_RightIndex>
                ;
        };

        right_index_tap: homey_right_index_tap {
            compatible = "zmk,behavior-macro-one-param";
            wait-ms = <0>;
            tap-ms = <0>;
            #binding-cells = <1>;
            bindings
                = <&macro_release
                    &kp LSFT &kp RSFT
                    &kp LALT &kp RALT
                    &kp LCTL &kp RCTL
                    &kp LGUI &kp RGUI>
                , <&macro_tap &kp RIGHT_INDEX_KEY>
                , <&macro_param_1to1>
                , <&macro_tap &kp MACRO_PLACEHOLDER>
                ;
        };

        #define RightIndex(key, layer_index) RightIndex_unroll(layer_index) (key)
        #define RightIndex_unroll(layer_index) RightIndex_concat(RightIndex_layer, layer_index)
        #define RightIndex_concat(prefix, layer_index) prefix ## layer_index
        #define RightIndex_layer0(key) right_index_bilateral RIGHT_INDEX_MOD key
        #define RightIndex_layer1(key) right_index RIGHT_INDEX_MOD key
        #define RightIndex_layer2(key) right_index RIGHT_INDEX_MOD key
        #define RightIndex_layer3(key) right_index RIGHT_INDEX_MOD key

// ▄▄▄▄▄▄▄▄▄▄▄▄▄▄▄▄▄▄▄▄▄▄▄▄▄▄▄▄▄▄▄▄▄▄▄▄▄▄▄▄▄▄▄▄▄▄▄▄▄▄▄▄▄▄▄▄▄▄▄▄▄▄▄▄▄▄▄▄▄▄▄▄▄▄▄▄▄▄▄▄▄▄▄▄▄▄▄▄▄▄▄▄▄▄▄▄▄▄▄▄▄▄▄▄▄▄▄▄▄▄▄▄▄▄▄▄▄▄▄▄▄▄▄▄▄▄▄▄▄▄▄▄▄▄▄▄▄▄▄▄▄▄▄▄▄▄▄▄▄
// RIGHT MIDDY BEHAVIORS
// ▄▄▄▄▄▄▄▄▄▄▄▄▄▄▄▄▄▄▄▄▄▄▄▄▄▄▄▄▄▄▄▄▄▄▄▄▄▄▄▄▄▄▄▄▄▄▄▄▄▄▄▄▄▄▄▄▄▄▄▄▄▄▄▄▄▄▄▄▄▄▄▄▄▄▄▄▄▄▄▄▄▄▄▄▄▄▄▄▄▄▄▄▄▄▄▄▄▄▄▄▄▄▄▄▄▄▄▄▄▄▄▄▄▄▄▄▄▄▄▄▄▄▄▄▄▄▄▄▄▄▄▄▄▄▄▄▄▄▄▄▄▄▄▄▄▄▄▄▄

        right_middy: homey_right_middy {
            compatible = "zmk,behavior-hold-tap";
            flavor = RIGHT_MIDDY_HOLDING_TYPE;
            hold-trigger-key-positions = <LEFT_HAND_KEYS THUMB_KEYS>;
            hold-trigger-on-release;
            tapping-term-ms = <RIGHT_MIDDY_HOLDING_TIME>;
            quick-tap-ms = <RIGHT_MIDDY_REPEAT_DECAY>;
            require-prior-idle-ms = <RIGHT_MIDDY_STREAK_DECAY>;
            #binding-cells = <2>;
            bindings = <&kp>, <&kp>;
        };

        right_middy_bilateral: homey_right_middy_bilateral {
            compatible = "zmk,behavior-hold-tap";
            flavor = RIGHT_MIDDY_HOLDING_TYPE;
            hold-trigger-key-positions = <LEFT_HAND_KEYS THUMB_KEYS>;
            hold-trigger-on-release;
            tapping-term-ms = <RIGHT_MIDDY_HOLDING_TIME>;
            quick-tap-ms = <RIGHT_MIDDY_REPEAT_DECAY>;
            require-prior-idle-ms = <RIGHT_MIDDY_STREAK_DECAY>;
            #binding-cells = <2>;
            bindings = <&right_middy_hold>, <&kp>;
        };

        right_middy_hold: homey_right_middy_hold {
            compatible = "zmk,behavior-macro-one-param";
            wait-ms = <0>;
            tap-ms = <0>;
            #binding-cells = <1>;
            bindings
                = <&macro_param_1to1>
                , <&macro_press &kp MACRO_PLACEHOLDER>
                , <&macro_press &mo LAYER_RightMiddy>
                , <&macro_pause_for_release>
                , <&macro_param_1to1>
                , <&macro_release &kp MACRO_PLACEHOLDER>
                , <&macro_release &mo LAYER_RightMiddy>
                ;
        };

        right_middy_tap: homey_right_middy_tap {
            compatible = "zmk,behavior-macro-one-param";
            wait-ms = <0>;
            tap-ms = <0>;
            #binding-cells = <1>;
            bindings
                = <&macro_release
                    &kp LSFT &kp RSFT
                    &kp LALT &kp RALT
                    &kp LCTL &kp RCTL
                    &kp LGUI &kp RGUI>
                , <&macro_tap &kp RIGHT_MIDDY_KEY>
                , <&macro_param_1to1>
                , <&macro_tap &kp MACRO_PLACEHOLDER>
                ;
        };

        #define RightMiddy(key, layer_index) RightMiddy_unroll(layer_index) (key)
        #define RightMiddy_unroll(layer_index) RightMiddy_concat(RightMiddy_layer, layer_index)
        #define RightMiddy_concat(prefix, layer_index) prefix ## layer_index
        #define RightMiddy_layer0(key) right_middy_bilateral RIGHT_MIDDY_MOD key
        #define RightMiddy_layer1(key) right_middy RIGHT_MIDDY_MOD key
        #define RightMiddy_layer2(key) right_middy RIGHT_MIDDY_MOD key
        #define RightMiddy_layer3(key) right_middy RIGHT_MIDDY_MOD key

// ▄▄▄▄▄▄▄▄▄▄▄▄▄▄▄▄▄▄▄▄▄▄▄▄▄▄▄▄▄▄▄▄▄▄▄▄▄▄▄▄▄▄▄▄▄▄▄▄▄▄▄▄▄▄▄▄▄▄▄▄▄▄▄▄▄▄▄▄▄▄▄▄▄▄▄▄▄▄▄▄▄▄▄▄▄▄▄▄▄▄▄▄▄▄▄▄▄▄▄▄▄▄▄▄▄▄▄▄▄▄▄▄▄▄▄▄▄▄▄▄▄▄▄▄▄▄▄▄▄▄▄▄▄▄▄▄▄▄▄▄▄▄▄▄▄▄▄▄▄
// RIGHT RINGY BEHAVIORS
// ▄▄▄▄▄▄▄▄▄▄▄▄▄▄▄▄▄▄▄▄▄▄▄▄▄▄▄▄▄▄▄▄▄▄▄▄▄▄▄▄▄▄▄▄▄▄▄▄▄▄▄▄▄▄▄▄▄▄▄▄▄▄▄▄▄▄▄▄▄▄▄▄▄▄▄▄▄▄▄▄▄▄▄▄▄▄▄▄▄▄▄▄▄▄▄▄▄▄▄▄▄▄▄▄▄▄▄▄▄▄▄▄▄▄▄▄▄▄▄▄▄▄▄▄▄▄▄▄▄▄▄▄▄▄▄▄▄▄▄▄▄▄▄▄▄▄▄▄▄

        right_ringy: homey_right_ringy {
            compatible = "zmk,behavior-hold-tap";
            flavor = RIGHT_RINGY_HOLDING_TYPE;
            hold-trigger-key-positions = <LEFT_HAND_KEYS THUMB_KEYS>;
            hold-trigger-on-release;
            tapping-term-ms = <RIGHT_RINGY_HOLDING_TIME>;
            quick-tap-ms = <RIGHT_RINGY_REPEAT_DECAY>;
            require-prior-idle-ms = <RIGHT_RINGY_STREAK_DECAY>;
            #binding-cells = <2>;
            bindings = <&kp>, <&kp>;
        };

        right_ringy_bilateral: homey_right_ringy_bilateral {
            compatible = "zmk,behavior-hold-tap";
            flavor = RIGHT_RINGY_HOLDING_TYPE;
            hold-trigger-key-positions = <LEFT_HAND_KEYS THUMB_KEYS>;
            hold-trigger-on-release;
            tapping-term-ms = <RIGHT_RINGY_HOLDING_TIME>;
            quick-tap-ms = <RIGHT_RINGY_REPEAT_DECAY>;
            require-prior-idle-ms = <RIGHT_RINGY_STREAK_DECAY>;
            #binding-cells = <2>;
            bindings = <&right_ringy_hold>, <&kp>;
        };

        right_ringy_hold: homey_right_ringy_hold {
            compatible = "zmk,behavior-macro-one-param";
            wait-ms = <0>;
            tap-ms = <0>;
            #binding-cells = <1>;
            bindings
                = <&macro_param_1to1>
                , <&macro_press &kp MACRO_PLACEHOLDER>
                , <&macro_press &mo LAYER_RightRingy>
                , <&macro_pause_for_release>
                , <&macro_param_1to1>
                , <&macro_release &kp MACRO_PLACEHOLDER>
                , <&macro_release &mo LAYER_RightRingy>
                ;
        };

        right_ringy_tap: homey_right_ringy_tap {
            compatible = "zmk,behavior-macro-one-param";
            wait-ms = <0>;
            tap-ms = <0>;
            #binding-cells = <1>;
            bindings
                = <&macro_release
                    &kp LSFT &kp RSFT
                    &kp LALT &kp RALT
                    &kp LCTL &kp RCTL
                    &kp LGUI &kp RGUI>
                , <&macro_tap &kp RIGHT_RINGY_KEY>
                , <&macro_param_1to1>
                , <&macro_tap &kp MACRO_PLACEHOLDER>
                ;
        };

        #define RightRingy(key, layer_index) RightRingy_unroll(layer_index) (key)
        #define RightRingy_unroll(layer_index) RightRingy_concat(RightRingy_layer, layer_index)
        #define RightRingy_concat(prefix, layer_index) prefix ## layer_index
        #define RightRingy_layer0(key) right_ringy_bilateral RIGHT_RINGY_MOD key
        #define RightRingy_layer1(key) right_ringy RIGHT_RINGY_MOD key
        #define RightRingy_layer2(key) right_ringy RIGHT_RINGY_MOD key
        #define RightRingy_layer3(key) right_ringy RIGHT_RINGY_MOD key

// ▄▄▄▄▄▄▄▄▄▄▄▄▄▄▄▄▄▄▄▄▄▄▄▄▄▄▄▄▄▄▄▄▄▄▄▄▄▄▄▄▄▄▄▄▄▄▄▄▄▄▄▄▄▄▄▄▄▄▄▄▄▄▄▄▄▄▄▄▄▄▄▄▄▄▄▄▄▄▄▄▄▄▄▄▄▄▄▄▄▄▄▄▄▄▄▄▄▄▄▄▄▄▄▄▄▄▄▄▄▄▄▄▄▄▄▄▄▄▄▄▄▄▄▄▄▄▄▄▄▄▄▄▄▄▄▄▄▄▄▄▄▄▄▄▄▄▄▄▄
// RIGHT PINKY BEHAVIORS
// ▄▄▄▄▄▄▄▄▄▄▄▄▄▄▄▄▄▄▄▄▄▄▄▄▄▄▄▄▄▄▄▄▄▄▄▄▄▄▄▄▄▄▄▄▄▄▄▄▄▄▄▄▄▄▄▄▄▄▄▄▄▄▄▄▄▄▄▄▄▄▄▄▄▄▄▄▄▄▄▄▄▄▄▄▄▄▄▄▄▄▄▄▄▄▄▄▄▄▄▄▄▄▄▄▄▄▄▄▄▄▄▄▄▄▄▄▄▄▄▄▄▄▄▄▄▄▄▄▄▄▄▄▄▄▄▄▄▄▄▄▄▄▄▄▄▄▄▄▄

        right_pinky: homey_right_pinky {
            compatible = "zmk,behavior-hold-tap";
            flavor = RIGHT_PINKY_HOLDING_TYPE;
            hold-trigger-key-positions = <LEFT_HAND_KEYS THUMB_KEYS>;
            hold-trigger-on-release;
            tapping-term-ms = <RIGHT_PINKY_HOLDING_TIME>;
            quick-tap-ms = <RIGHT_PINKY_REPEAT_DECAY>;
            require-prior-idle-ms = <RIGHT_PINKY_STREAK_DECAY>;
            #binding-cells = <2>;
            bindings = <&kp>, <&kp>;
        };

        right_pinky_bilateral: homey_right_pinky_bilateral {
            compatible = "zmk,behavior-hold-tap";
            flavor = RIGHT_PINKY_HOLDING_TYPE;
            hold-trigger-key-positions = <LEFT_HAND_KEYS THUMB_KEYS>;
            hold-trigger-on-release;
            tapping-term-ms = <RIGHT_PINKY_HOLDING_TIME>;
            quick-tap-ms = <RIGHT_PINKY_REPEAT_DECAY>;
            require-prior-idle-ms = <RIGHT_PINKY_STREAK_DECAY>;
            #binding-cells = <2>;
            bindings = <&right_pinky_hold>, <&kp>;
        };

        right_pinky_hold: homey_right_pinky_hold {
            compatible = "zmk,behavior-macro-one-param";
            wait-ms = <0>;
            tap-ms = <0>;
            #binding-cells = <1>;
            bindings
                = <&macro_param_1to1>
                , <&macro_press &kp MACRO_PLACEHOLDER>
                , <&macro_press &mo LAYER_RightPinky>
                , <&macro_pause_for_release>
                , <&macro_param_1to1>
                , <&macro_release &kp MACRO_PLACEHOLDER>
                , <&macro_release &mo LAYER_RightPinky>
                ;
        };

        right_pinky_tap: homey_right_pinky_tap {
            compatible = "zmk,behavior-macro-one-param";
            wait-ms = <0>;
            tap-ms = <0>;
            #binding-cells = <1>;
            bindings
                = <&macro_release
                    &kp LSFT &kp RSFT
                    &kp LALT &kp RALT
                    &kp LCTL &kp RCTL
                    &kp LGUI &kp RGUI>
                , <&macro_tap &kp RIGHT_PINKY_KEY>
                , <&macro_param_1to1>
                , <&macro_tap &kp MACRO_PLACEHOLDER>
                ;
        };

        #define RightPinky(key, layer_index) RightPinky_unroll(layer_index) (key)
        #define RightPinky_unroll(layer_index) RightPinky_concat(RightPinky_layer, layer_index)
        #define RightPinky_concat(prefix, layer_index) prefix ## layer_index
        #define RightPinky_layer0(key) right_pinky_bilateral RIGHT_PINKY_MOD key
        #define RightPinky_layer1(key) right_pinky RIGHT_PINKY_MOD key
        #define RightPinky_layer2(key) right_pinky RIGHT_PINKY_MOD key
        #define RightPinky_layer3(key) right_pinky RIGHT_PINKY_MOD key

// ▄▄▄▄▄▄▄▄▄▄▄▄▄▄▄▄▄▄▄▄▄▄▄▄▄▄▄▄▄▄▄▄▄▄▄▄▄▄▄▄▄▄▄▄▄▄▄▄▄▄▄▄▄▄▄▄▄▄▄▄▄▄▄▄▄▄▄▄▄▄▄▄▄▄▄▄▄▄▄▄▄▄▄▄▄▄▄▄▄▄▄▄▄▄▄▄▄▄▄▄▄▄▄▄▄▄▄▄▄▄▄▄▄▄▄▄▄▄▄▄▄▄▄▄▄▄▄▄▄▄▄▄▄▄▄▄▄▄▄▄▄▄▄▄▄▄▄▄▄
// LEFT HAND CHORD BEHAVIORS
// ▄▄▄▄▄▄▄▄▄▄▄▄▄▄▄▄▄▄▄▄▄▄▄▄▄▄▄▄▄▄▄▄▄▄▄▄▄▄▄▄▄▄▄▄▄▄▄▄▄▄▄▄▄▄▄▄▄▄▄▄▄▄▄▄▄▄▄▄▄▄▄▄▄▄▄▄▄▄▄▄▄▄▄▄▄▄▄▄▄▄▄▄▄▄▄▄▄▄▄▄▄▄▄▄▄▄▄▄▄▄▄▄▄▄▄▄▄▄▄▄▄▄▄▄▄▄▄▄▄▄▄▄▄▄▄▄▄▄▄▄▄▄▄▄▄▄▄▄▄

        // Pinky + Ringy chord
        left_pinky_ringy: homey_left_pinky_ringy {
            compatible = "zmk,behavior-hold-tap";
            flavor = LEFT_PINKY_HOLDING_TYPE;
            hold-trigger-key-positions = <RIGHT_HAND_KEYS THUMB_KEYS>;
            hold-trigger-on-release;
            tapping-term-ms = <LEFT_PINKY_HOLDING_TIME>;
            quick-tap-ms = <LEFT_PINKY_REPEAT_DECAY>;
            require-prior-idle-ms = <LEFT_PINKY_STREAK_DECAY>;
            #binding-cells = <2>;
            bindings = <&kp>, <&kp>;
        };

        left_pinky_ringy_bilateral: homey_left_pinky_ringy_bilateral {
            compatible = "zmk,behavior-hold-tap";
            flavor = LEFT_PINKY_HOLDING_TYPE;
            hold-trigger-key-positions = <RIGHT_HAND_KEYS THUMB_KEYS>;
            hold-trigger-on-release;
            tapping-term-ms = <LEFT_PINKY_HOLDING_TIME>;
            quick-tap-ms = <LEFT_PINKY_REPEAT_DECAY>;
            require-prior-idle-ms = <LEFT_PINKY_STREAK_DECAY>;
            #binding-cells = <2>;
            bindings = <&kp>, <&left_pinky_tap>;
        };

        #define LeftPinkyRingy left_pinky_ringy_bilateral LEFT_RINGY_MOD LEFT_RINGY_KEY

        // Pinky + Middy chord
        left_pinky_middy: homey_left_pinky_middy {
            compatible = "zmk,behavior-hold-tap";
            flavor = LEFT_PINKY_HOLDING_TYPE;
            hold-trigger-key-positions = <RIGHT_HAND_KEYS THUMB_KEYS>;
            hold-trigger-on-release;
            tapping-term-ms = <LEFT_PINKY_HOLDING_TIME>;
            quick-tap-ms = <LEFT_PINKY_REPEAT_DECAY>;
            require-prior-idle-ms = <LEFT_PINKY_STREAK_DECAY>;
            #binding-cells = <2>;
            bindings = <&kp>, <&kp>;
        };

        left_pinky_middy_bilateral: homey_left_pinky_middy_bilateral {
            compatible = "zmk,behavior-hold-tap";
            flavor = LEFT_PINKY_HOLDING_TYPE;
            hold-trigger-key-positions = <RIGHT_HAND_KEYS THUMB_KEYS>;
            hold-trigger-on-release;
            tapping-term-ms = <LEFT_PINKY_HOLDING_TIME>;
            quick-tap-ms = <LEFT_PINKY_REPEAT_DECAY>;
            require-prior-idle-ms = <LEFT_PINKY_STREAK_DECAY>;
            #binding-cells = <2>;
            bindings = <&kp>, <&left_pinky_tap>;
        };

        #define LeftPinkyMiddy left_pinky_middy_bilateral LEFT_MIDDY_MOD LEFT_MIDDY_KEY

        // Pinky + Index chord
        left_pinky_index: homey_left_pinky_index {
            compatible = "zmk,behavior-hold-tap";
            flavor = LEFT_PINKY_HOLDING_TYPE;
            hold-trigger-key-positions = <RIGHT_HAND_KEYS THUMB_KEYS>;
            hold-trigger-on-release;
            tapping-term-ms = <LEFT_PINKY_HOLDING_TIME>;
            quick-tap-ms = <LEFT_PINKY_REPEAT_DECAY>;
            require-prior-idle-ms = <LEFT_PINKY_STREAK_DECAY>;
            #binding-cells = <2>;
            bindings = <&kp>, <&kp>;
        };

        left_pinky_index_bilateral: homey_left_pinky_index_bilateral {
            compatible = "zmk,behavior-hold-tap";
            flavor = LEFT_PINKY_HOLDING_TYPE;
            hold-trigger-key-positions = <RIGHT_HAND_KEYS THUMB_KEYS>;
            hold-trigger-on-release;
            tapping-term-ms = <LEFT_PINKY_HOLDING_TIME>;
            quick-tap-ms = <LEFT_PINKY_REPEAT_DECAY>;
            require-prior-idle-ms = <LEFT_PINKY_STREAK_DECAY>;
            #binding-cells = <2>;
            bindings = <&kp>, <&left_pinky_tap>;
        };

        #define LeftPinkyIndex left_pinky_index_bilateral LEFT_INDEX_MOD LEFT_INDEX_KEY

        // Ringy + Pinky chord
        left_ringy_pinky: homey_left_ringy_pinky {
            compatible = "zmk,behavior-hold-tap";
            flavor = LEFT_RINGY_HOLDING_TYPE;
            hold-trigger-key-positions = <RIGHT_HAND_KEYS THUMB_KEYS>;
            hold-trigger-on-release;
            tapping-term-ms = <LEFT_RINGY_HOLDING_TIME>;
            quick-tap-ms = <LEFT_RINGY_REPEAT_DECAY>;
            require-prior-idle-ms = <LEFT_RINGY_STREAK_DECAY>;
            #binding-cells = <2>;
            bindings = <&kp>, <&kp>;
        };

        left_ringy_pinky_bilateral: homey_left_ringy_pinky_bilateral {
            compatible = "zmk,behavior-hold-tap";
            flavor = LEFT_RINGY_HOLDING_TYPE;
            hold-trigger-key-positions = <RIGHT_HAND_KEYS THUMB_KEYS>;
            hold-trigger-on-release;
            tapping-term-ms = <LEFT_RINGY_HOLDING_TIME>;
            quick-tap-ms = <LEFT_RINGY_REPEAT_DECAY>;
            require-prior-idle-ms = <LEFT_RINGY_STREAK_DECAY>;
            #binding-cells = <2>;
            bindings = <&kp>, <&left_ringy_tap>;
        };

        #define LeftRingyPinky left_ringy_pinky_bilateral LEFT_PINKY_MOD LEFT_PINKY_KEY

        // Ringy + Middy chord
        left_ringy_middy: homey_left_ringy_middy {
            compatible = "zmk,behavior-hold-tap";
            flavor = LEFT_RINGY_HOLDING_TYPE;
            hold-trigger-key-positions = <RIGHT_HAND_KEYS THUMB_KEYS>;
            hold-trigger-on-release;
            tapping-term-ms = <LEFT_RINGY_HOLDING_TIME>;
            quick-tap-ms = <LEFT_RINGY_REPEAT_DECAY>;
            require-prior-idle-ms = <LEFT_RINGY_STREAK_DECAY>;
            #binding-cells = <2>;
            bindings = <&kp>, <&kp>;
        };

        left_ringy_middy_bilateral: homey_left_ringy_middy_bilateral {
            compatible = "zmk,behavior-hold-tap";
            flavor = LEFT_RINGY_HOLDING_TYPE;
            hold-trigger-key-positions = <RIGHT_HAND_KEYS THUMB_KEYS>;
            hold-trigger-on-release;
            tapping-term-ms = <LEFT_RINGY_HOLDING_TIME>;
            quick-tap-ms = <LEFT_RINGY_REPEAT_DECAY>;
            require-prior-idle-ms = <LEFT_RINGY_STREAK_DECAY>;
            #binding-cells = <2>;
            bindings = <&kp>, <&left_ringy_tap>;
        };

        #define LeftRingyMiddy left_ringy_middy_bilateral LEFT_MIDDY_MOD LEFT_MIDDY_KEY

        // Ringy + Index chord
        left_ringy_index: homey_left_ringy_index {
            compatible = "zmk,behavior-hold-tap";
            flavor = LEFT_RINGY_HOLDING_TYPE;
            hold-trigger-key-positions = <RIGHT_HAND_KEYS THUMB_KEYS>;
            hold-trigger-on-release;
            tapping-term-ms = <LEFT_RINGY_HOLDING_TIME>;
            quick-tap-ms = <LEFT_RINGY_REPEAT_DECAY>;
            require-prior-idle-ms = <LEFT_RINGY_STREAK_DECAY>;
            #binding-cells = <2>;
            bindings = <&kp>, <&kp>;
        };

        left_ringy_index_bilateral: homey_left_ringy_index_bilateral {
            compatible = "zmk,behavior-hold-tap";
            flavor = LEFT_RINGY_HOLDING_TYPE;
            hold-trigger-key-positions = <RIGHT_HAND_KEYS THUMB_KEYS>;
            hold-trigger-on-release;
            tapping-term-ms = <LEFT_RINGY_HOLDING_TIME>;
            quick-tap-ms = <LEFT_RINGY_REPEAT_DECAY>;
            require-prior-idle-ms = <LEFT_RINGY_STREAK_DECAY>;
            #binding-cells = <2>;
            bindings = <&kp>, <&left_ringy_tap>;
        };

        #define LeftRingyIndex left_ringy_index_bilateral LEFT_INDEX_MOD LEFT_INDEX_KEY

        // Middy + Pinky chord
        left_middy_pinky: homey_left_middy_pinky {
            compatible = "zmk,behavior-hold-tap";
            flavor = LEFT_MIDDY_HOLDING_TYPE;
            hold-trigger-key-positions = <RIGHT_HAND_KEYS THUMB_KEYS>;
            hold-trigger-on-release;
            tapping-term-ms = <LEFT_MIDDY_HOLDING_TIME>;
            quick-tap-ms = <LEFT_MIDDY_REPEAT_DECAY>;
            require-prior-idle-ms = <LEFT_MIDDY_STREAK_DECAY>;
            #binding-cells = <2>;
            bindings = <&kp>, <&kp>;
        };

        left_middy_pinky_bilateral: homey_left_middy_pinky_bilateral {
            compatible = "zmk,behavior-hold-tap";
            flavor = LEFT_MIDDY_HOLDING_TYPE;
            hold-trigger-key-positions = <RIGHT_HAND_KEYS THUMB_KEYS>;
            hold-trigger-on-release;
            tapping-term-ms = <LEFT_MIDDY_HOLDING_TIME>;
            quick-tap-ms = <LEFT_MIDDY_REPEAT_DECAY>;
            require-prior-idle-ms = <LEFT_MIDDY_STREAK_DECAY>;
            #binding-cells = <2>;
            bindings = <&kp>, <&left_middy_tap>;
        };

        #define LeftMiddyPinky left_middy_pinky_bilateral LEFT_PINKY_MOD LEFT_PINKY_KEY

        // Middy + Ringy chord
        left_middy_ringy: homey_left_middy_ringy {
            compatible = "zmk,behavior-hold-tap";
            flavor = LEFT_MIDDY_HOLDING_TYPE;
            hold-trigger-key-positions = <RIGHT_HAND_KEYS THUMB_KEYS>;
            hold-trigger-on-release;
            tapping-term-ms = <LEFT_MIDDY_HOLDING_TIME>;
            quick-tap-ms = <LEFT_MIDDY_REPEAT_DECAY>;
            require-prior-idle-ms = <LEFT_MIDDY_STREAK_DECAY>;
            #binding-cells = <2>;
            bindings = <&kp>, <&kp>;
        };

        left_middy_ringy_bilateral: homey_left_middy_ringy_bilateral {
            compatible = "zmk,behavior-hold-tap";
            flavor = LEFT_MIDDY_HOLDING_TYPE;
            hold-trigger-key-positions = <RIGHT_HAND_KEYS THUMB_KEYS>;
            hold-trigger-on-release;
            tapping-term-ms = <LEFT_MIDDY_HOLDING_TIME>;
            quick-tap-ms = <LEFT_MIDDY_REPEAT_DECAY>;
            require-prior-idle-ms = <LEFT_MIDDY_STREAK_DECAY>;
            #binding-cells = <2>;
            bindings = <&kp>, <&left_middy_tap>;
        };

        #define LeftMiddyRingy left_middy_ringy_bilateral LEFT_RINGY_MOD LEFT_RINGY_KEY

        // Middy + Index chord
        left_middy_index: homey_left_middy_index {
            compatible = "zmk,behavior-hold-tap";
            flavor = LEFT_MIDDY_HOLDING_TYPE;
            hold-trigger-key-positions = <RIGHT_HAND_KEYS THUMB_KEYS>;
            hold-trigger-on-release;
            tapping-term-ms = <LEFT_MIDDY_HOLDING_TIME>;
            quick-tap-ms = <LEFT_MIDDY_REPEAT_DECAY>;
            require-prior-idle-ms = <LEFT_MIDDY_STREAK_DECAY>;
            #binding-cells = <2>;
            bindings = <&kp>, <&kp>;
        };

        left_middy_index_bilateral: homey_left_middy_index_bilateral {
            compatible = "zmk,behavior-hold-tap";
            flavor = LEFT_MIDDY_HOLDING_TYPE;
            hold-trigger-key-positions = <RIGHT_HAND_KEYS THUMB_KEYS>;
            hold-trigger-on-release;
            tapping-term-ms = <LEFT_MIDDY_HOLDING_TIME>;
            quick-tap-ms = <LEFT_MIDDY_REPEAT_DECAY>;
            require-prior-idle-ms = <LEFT_MIDDY_STREAK_DECAY>;
            #binding-cells = <2>;
            bindings = <&kp>, <&left_middy_tap>;
        };

        #define LeftMiddyIndex left_middy_index_bilateral LEFT_INDEX_MOD LEFT_INDEX_KEY

        // Index + Pinky chord
        left_index_pinky: homey_left_index_pinky {
            compatible = "zmk,behavior-hold-tap";
            flavor = LEFT_INDEX_HOLDING_TYPE;
            hold-trigger-key-positions = <RIGHT_HAND_KEYS THUMB_KEYS>;
            hold-trigger-on-release;
            tapping-term-ms = <LEFT_INDEX_HOLDING_TIME>;
            quick-tap-ms = <LEFT_INDEX_REPEAT_DECAY>;
            require-prior-idle-ms = <LEFT_INDEX_STREAK_DECAY>;
            #binding-cells = <2>;
            bindings = <&kp>, <&kp>;
        };

        left_index_pinky_bilateral: homey_left_index_pinky_bilateral {
            compatible = "zmk,behavior-hold-tap";
            flavor = LEFT_INDEX_HOLDING_TYPE;
            hold-trigger-key-positions = <RIGHT_HAND_KEYS THUMB_KEYS>;
            hold-trigger-on-release;
            tapping-term-ms = <LEFT_INDEX_HOLDING_TIME>;
            quick-tap-ms = <LEFT_INDEX_REPEAT_DECAY>;
            require-prior-idle-ms = <LEFT_INDEX_STREAK_DECAY>;
            #binding-cells = <2>;
            bindings = <&kp>, <&left_index_tap>;
        };

        #define LeftIndexPinky left_index_pinky_bilateral LEFT_PINKY_MOD LEFT_PINKY_KEY

        // Index + Ringy chord
        left_index_ringy: homey_left_index_ringy {
            compatible = "zmk,behavior-hold-tap";
            flavor = LEFT_INDEX_HOLDING_TYPE;
            hold-trigger-key-positions = <RIGHT_HAND_KEYS THUMB_KEYS>;
            hold-trigger-on-release;
            tapping-term-ms = <LEFT_INDEX_HOLDING_TIME>;
            quick-tap-ms = <LEFT_INDEX_REPEAT_DECAY>;
            require-prior-idle-ms = <LEFT_INDEX_STREAK_DECAY>;
            #binding-cells = <2>;
            bindings = <&kp>, <&kp>;
        };

        left_index_ringy_bilateral: homey_left_index_ringy_bilateral {
            compatible = "zmk,behavior-hold-tap";
            flavor = LEFT_INDEX_HOLDING_TYPE;
            hold-trigger-key-positions = <RIGHT_HAND_KEYS THUMB_KEYS>;
            hold-trigger-on-release;
            tapping-term-ms = <LEFT_INDEX_HOLDING_TIME>;
            quick-tap-ms = <LEFT_INDEX_REPEAT_DECAY>;
            require-prior-idle-ms = <LEFT_INDEX_STREAK_DECAY>;
            #binding-cells = <2>;
            bindings = <&kp>, <&left_index_tap>;
        };

        #define LeftIndexRingy left_index_ringy_bilateral LEFT_RINGY_MOD LEFT_RINGY_KEY

        // Index + Middy chord
        left_index_middy: homey_left_index_middy {
            compatible = "zmk,behavior-hold-tap";
            flavor = LEFT_INDEX_HOLDING_TYPE;
            hold-trigger-key-positions = <RIGHT_HAND_KEYS THUMB_KEYS>;
            hold-trigger-on-release;
            tapping-term-ms = <LEFT_INDEX_HOLDING_TIME>;
            quick-tap-ms = <LEFT_INDEX_REPEAT_DECAY>;
            require-prior-idle-ms = <LEFT_INDEX_STREAK_DECAY>;
            #binding-cells = <2>;
            bindings = <&kp>, <&kp>;
        };

        left_index_middy_bilateral: homey_left_index_middy_bilateral {
            compatible = "zmk,behavior-hold-tap";
            flavor = LEFT_INDEX_HOLDING_TYPE;
            hold-trigger-key-positions = <RIGHT_HAND_KEYS THUMB_KEYS>;
            hold-trigger-on-release;
            tapping-term-ms = <LEFT_INDEX_HOLDING_TIME>;
            quick-tap-ms = <LEFT_INDEX_REPEAT_DECAY>;
            require-prior-idle-ms = <LEFT_INDEX_STREAK_DECAY>;
            #binding-cells = <2>;
            bindings = <&kp>, <&left_index_tap>;
        };

        #define LeftIndexMiddy left_index_middy_bilateral LEFT_MIDDY_MOD LEFT_MIDDY_KEY

// ▄▄▄▄▄▄▄▄▄▄▄▄▄▄▄▄▄▄▄▄▄▄▄▄▄▄▄▄▄▄▄▄▄▄▄▄▄▄▄▄▄▄▄▄▄▄▄▄▄▄▄▄▄▄▄▄▄▄▄▄▄▄▄▄▄▄▄▄▄▄▄▄▄▄▄▄▄▄▄▄▄▄▄▄▄▄▄▄▄▄▄▄▄▄▄▄▄▄▄▄▄▄▄▄▄▄▄▄▄▄▄▄▄▄▄▄▄▄▄▄▄▄▄▄▄▄▄▄▄▄▄▄▄▄▄▄▄▄▄▄▄▄▄▄▄▄▄▄▄
// RIGHT HAND CHORD BEHAVIORS
// ▄▄▄▄▄▄▄▄▄▄▄▄▄▄▄▄▄▄▄▄▄▄▄▄▄▄▄▄▄▄▄▄▄▄▄▄▄▄▄▄▄▄▄▄▄▄▄▄▄▄▄▄▄▄▄▄▄▄▄▄▄▄▄▄▄▄▄▄▄▄▄▄▄▄▄▄▄▄▄▄▄▄▄▄▄▄▄▄▄▄▄▄▄▄▄▄▄▄▄▄▄▄▄▄▄▄▄▄▄▄▄▄▄▄▄▄▄▄▄▄▄▄▄▄▄▄▄▄▄▄▄▄▄▄▄▄▄▄▄▄▄▄▄▄▄▄▄▄▄

        // Index + Pinky chord
        right_index_pinky: homey_right_index_pinky {
            compatible = "zmk,behavior-hold-tap";
            flavor = RIGHT_INDEX_HOLDING_TYPE;
            hold-trigger-key-positions = <LEFT_HAND_KEYS THUMB_KEYS>;
            hold-trigger-on-release;
            tapping-term-ms = <RIGHT_INDEX_HOLDING_TIME>;
            quick-tap-ms = <RIGHT_INDEX_REPEAT_DECAY>;
            require-prior-idle-ms = <RIGHT_INDEX_STREAK_DECAY>;
            #binding-cells = <2>;
            bindings = <&kp>, <&kp>;
        };

        right_index_pinky_bilateral: homey_right_index_pinky_bilateral {
            compatible = "zmk,behavior-hold-tap";
            flavor = RIGHT_INDEX_HOLDING_TYPE;
            hold-trigger-key-positions = <LEFT_HAND_KEYS THUMB_KEYS>;
            hold-trigger-on-release;
            tapping-term-ms = <RIGHT_INDEX_HOLDING_TIME>;
            quick-tap-ms = <RIGHT_INDEX_REPEAT_DECAY>;
            require-prior-idle-ms = <RIGHT_INDEX_STREAK_DECAY>;
            #binding-cells = <2>;
            bindings = <&kp>, <&right_index_tap>;
        };

        #define RightIndexPinky right_index_pinky_bilateral RIGHT_PINKY_MOD RIGHT_PINKY_KEY

        // Index + Ringy chord
        right_index_ringy: homey_right_index_ringy {
            compatible = "zmk,behavior-hold-tap";
            flavor = RIGHT_INDEX_HOLDING_TYPE;
            hold-trigger-key-positions = <LEFT_HAND_KEYS THUMB_KEYS>;
            hold-trigger-on-release;
            tapping-term-ms = <RIGHT_INDEX_HOLDING_TIME>;
            quick-tap-ms = <RIGHT_INDEX_REPEAT_DECAY>;
            require-prior-idle-ms = <RIGHT_INDEX_STREAK_DECAY>;
            #binding-cells = <2>;
            bindings = <&kp>, <&kp>;
        };

        right_index_ringy_bilateral: homey_right_index_ringy_bilateral {
            compatible = "zmk,behavior-hold-tap";
            flavor = RIGHT_INDEX_HOLDING_TYPE;
            hold-trigger-key-positions = <LEFT_HAND_KEYS THUMB_KEYS>;
            hold-trigger-on-release;
            tapping-term-ms = <RIGHT_INDEX_HOLDING_TIME>;
            quick-tap-ms = <RIGHT_INDEX_REPEAT_DECAY>;
            require-prior-idle-ms = <RIGHT_INDEX_STREAK_DECAY>;
            #binding-cells = <2>;
            bindings = <&kp>, <&right_index_tap>;
        };

        #define RightIndexRingy right_index_ringy_bilateral RIGHT_RINGY_MOD RIGHT_RINGY_KEY

        // Index + Middy chord
        right_index_middy: homey_right_index_middy {
            compatible = "zmk,behavior-hold-tap";
            flavor = RIGHT_INDEX_HOLDING_TYPE;
            hold-trigger-key-positions = <LEFT_HAND_KEYS THUMB_KEYS>;
            hold-trigger-on-release;
            tapping-term-ms = <RIGHT_INDEX_HOLDING_TIME>;
            quick-tap-ms = <RIGHT_INDEX_REPEAT_DECAY>;
            require-prior-idle-ms = <RIGHT_INDEX_STREAK_DECAY>;
            #binding-cells = <2>;
            bindings = <&kp>, <&kp>;
        };

        right_index_middy_bilateral: homey_right_index_middy_bilateral {
            compatible = "zmk,behavior-hold-tap";
            flavor = RIGHT_INDEX_HOLDING_TYPE;
            hold-trigger-key-positions = <LEFT_HAND_KEYS THUMB_KEYS>;
            hold-trigger-on-release;
            tapping-term-ms = <RIGHT_INDEX_HOLDING_TIME>;
            quick-tap-ms = <RIGHT_INDEX_REPEAT_DECAY>;
            require-prior-idle-ms = <RIGHT_INDEX_STREAK_DECAY>;
            #binding-cells = <2>;
            bindings = <&kp>, <&right_index_tap>;
        };

        #define RightIndexMiddy right_index_middy_bilateral RIGHT_MIDDY_MOD RIGHT_MIDDY_KEY

        // Middy + Pinky chord
        right_middy_pinky: homey_right_middy_pinky {
            compatible = "zmk,behavior-hold-tap";
            flavor = RIGHT_MIDDY_HOLDING_TYPE;
            hold-trigger-key-positions = <LEFT_HAND_KEYS THUMB_KEYS>;
            hold-trigger-on-release;
            tapping-term-ms = <RIGHT_MIDDY_HOLDING_TIME>;
            quick-tap-ms = <RIGHT_MIDDY_REPEAT_DECAY>;
            require-prior-idle-ms = <RIGHT_MIDDY_STREAK_DECAY>;
            #binding-cells = <2>;
            bindings = <&kp>, <&kp>;
        };

        right_middy_pinky_bilateral: homey_right_middy_pinky_bilateral {
            compatible = "zmk,behavior-hold-tap";
            flavor = RIGHT_MIDDY_HOLDING_TYPE;
            hold-trigger-key-positions = <LEFT_HAND_KEYS THUMB_KEYS>;
            hold-trigger-on-release;
            tapping-term-ms = <RIGHT_MIDDY_HOLDING_TIME>;
            quick-tap-ms = <RIGHT_MIDDY_REPEAT_DECAY>;
            require-prior-idle-ms = <RIGHT_MIDDY_STREAK_DECAY>;
            #binding-cells = <2>;
            bindings = <&kp>, <&right_middy_tap>;
        };

        #define RightMiddyPinky right_middy_pinky_bilateral RIGHT_PINKY_MOD RIGHT_PINKY_KEY

        // Middy + Ringy chord
        right_middy_ringy: homey_right_middy_ringy {
            compatible = "zmk,behavior-hold-tap";
            flavor = RIGHT_MIDDY_HOLDING_TYPE;
            hold-trigger-key-positions = <LEFT_HAND_KEYS THUMB_KEYS>;
            hold-trigger-on-release;
            tapping-term-ms = <RIGHT_MIDDY_HOLDING_TIME>;
            quick-tap-ms = <RIGHT_MIDDY_REPEAT_DECAY>;
            require-prior-idle-ms = <RIGHT_MIDDY_STREAK_DECAY>;
            #binding-cells = <2>;
            bindings = <&kp>, <&kp>;
        };

        right_middy_ringy_bilateral: homey_right_middy_ringy_bilateral {
            compatible = "zmk,behavior-hold-tap";
            flavor = RIGHT_MIDDY_HOLDING_TYPE;
            hold-trigger-key-positions = <LEFT_HAND_KEYS THUMB_KEYS>;
            hold-trigger-on-release;
            tapping-term-ms = <RIGHT_MIDDY_HOLDING_TIME>;
            quick-tap-ms = <RIGHT_MIDDY_REPEAT_DECAY>;
            require-prior-idle-ms = <RIGHT_MIDDY_STREAK_DECAY>;
            #binding-cells = <2>;
            bindings = <&kp>, <&right_middy_tap>;
        };

        #define RightMiddyRingy right_middy_ringy_bilateral RIGHT_RINGY_MOD RIGHT_RINGY_KEY

        // Middy + Index chord
        right_middy_index: homey_right_middy_index {
            compatible = "zmk,behavior-hold-tap";
            flavor = RIGHT_MIDDY_HOLDING_TYPE;
            hold-trigger-key-positions = <LEFT_HAND_KEYS THUMB_KEYS>;
            hold-trigger-on-release;
            tapping-term-ms = <RIGHT_MIDDY_HOLDING_TIME>;
            quick-tap-ms = <RIGHT_MIDDY_REPEAT_DECAY>;
            require-prior-idle-ms = <RIGHT_MIDDY_STREAK_DECAY>;
            #binding-cells = <2>;
            bindings = <&kp>, <&kp>;
        };

        right_middy_index_bilateral: homey_right_middy_index_bilateral {
            compatible = "zmk,behavior-hold-tap";
            flavor = RIGHT_MIDDY_HOLDING_TYPE;
            hold-trigger-key-positions = <LEFT_HAND_KEYS THUMB_KEYS>;
            hold-trigger-on-release;
            tapping-term-ms = <RIGHT_MIDDY_HOLDING_TIME>;
            quick-tap-ms = <RIGHT_MIDDY_REPEAT_DECAY>;
            require-prior-idle-ms = <RIGHT_MIDDY_STREAK_DECAY>;
            #binding-cells = <2>;
            bindings = <&kp>, <&right_middy_tap>;
        };

        #define RightMiddyIndex right_middy_index_bilateral RIGHT_INDEX_MOD RIGHT_INDEX_KEY

        // Ringy + Pinky chord
        right_ringy_pinky: homey_right_ringy_pinky {
            compatible = "zmk,behavior-hold-tap";
            flavor = RIGHT_RINGY_HOLDING_TYPE;
            hold-trigger-key-positions = <LEFT_HAND_KEYS THUMB_KEYS>;
            hold-trigger-on-release;
            tapping-term-ms = <RIGHT_RINGY_HOLDING_TIME>;
            quick-tap-ms = <RIGHT_RINGY_REPEAT_DECAY>;
            require-prior-idle-ms = <RIGHT_RINGY_STREAK_DECAY>;
            #binding-cells = <2>;
            bindings = <&kp>, <&kp>;
        };

        right_ringy_pinky_bilateral: homey_right_ringy_pinky_bilateral {
            compatible = "zmk,behavior-hold-tap";
            flavor = RIGHT_RINGY_HOLDING_TYPE;
            hold-trigger-key-positions = <LEFT_HAND_KEYS THUMB_KEYS>;
            hold-trigger-on-release;
            tapping-term-ms = <RIGHT_RINGY_HOLDING_TIME>;
            quick-tap-ms = <RIGHT_RINGY_REPEAT_DECAY>;
            require-prior-idle-ms = <RIGHT_RINGY_STREAK_DECAY>;
            #binding-cells = <2>;
            bindings = <&kp>, <&right_ringy_tap>;
        };

        #define RightRingyPinky right_ringy_pinky_bilateral RIGHT_PINKY_MOD RIGHT_PINKY_KEY

        // Ringy + Middy chord
        right_ringy_middy: homey_right_ringy_middy {
            compatible = "zmk,behavior-hold-tap";
            flavor = RIGHT_RINGY_HOLDING_TYPE;
            hold-trigger-key-positions = <LEFT_HAND_KEYS THUMB_KEYS>;
            hold-trigger-on-release;
            tapping-term-ms = <RIGHT_RINGY_HOLDING_TIME>;
            quick-tap-ms = <RIGHT_RINGY_REPEAT_DECAY>;
            require-prior-idle-ms = <RIGHT_RINGY_STREAK_DECAY>;
            #binding-cells = <2>;
            bindings = <&kp>, <&kp>;
        };

        right_ringy_middy_bilateral: homey_right_ringy_middy_bilateral {
            compatible = "zmk,behavior-hold-tap";
            flavor = RIGHT_RINGY_HOLDING_TYPE;
            hold-trigger-key-positions = <LEFT_HAND_KEYS THUMB_KEYS>;
            hold-trigger-on-release;
            tapping-term-ms = <RIGHT_RINGY_HOLDING_TIME>;
            quick-tap-ms = <RIGHT_RINGY_REPEAT_DECAY>;
            require-prior-idle-ms = <RIGHT_RINGY_STREAK_DECAY>;
            #binding-cells = <2>;
            bindings = <&kp>, <&right_ringy_tap>;
        };

        #define RightRingyMiddy right_ringy_middy_bilateral RIGHT_MIDDY_MOD RIGHT_MIDDY_KEY

        // Ringy + Index chord
        right_ringy_index: homey_right_ringy_index {
            compatible = "zmk,behavior-hold-tap";
            flavor = RIGHT_RINGY_HOLDING_TYPE;
            hold-trigger-key-positions = <LEFT_HAND_KEYS THUMB_KEYS>;
            hold-trigger-on-release;
            tapping-term-ms = <RIGHT_RINGY_HOLDING_TIME>;
            quick-tap-ms = <RIGHT_RINGY_REPEAT_DECAY>;
            require-prior-idle-ms = <RIGHT_RINGY_STREAK_DECAY>;
            #binding-cells = <2>;
            bindings = <&kp>, <&kp>;
        };

        right_ringy_index_bilateral: homey_right_ringy_index_bilateral {
            compatible = "zmk,behavior-hold-tap";
            flavor = RIGHT_RINGY_HOLDING_TYPE;
            hold-trigger-key-positions = <LEFT_HAND_KEYS THUMB_KEYS>;
            hold-trigger-on-release;
            tapping-term-ms = <RIGHT_RINGY_HOLDING_TIME>;
            quick-tap-ms = <RIGHT_RINGY_REPEAT_DECAY>;
            require-prior-idle-ms = <RIGHT_RINGY_STREAK_DECAY>;
            #binding-cells = <2>;
            bindings = <&kp>, <&right_ringy_tap>;
        };

        #define RightRingyIndex right_ringy_index_bilateral RIGHT_INDEX_MOD RIGHT_INDEX_KEY

        // Pinky + Ringy chord
        right_pinky_ringy: homey_right_pinky_ringy {
            compatible = "zmk,behavior-hold-tap";
            flavor = RIGHT_PINKY_HOLDING_TYPE;
            hold-trigger-key-positions = <LEFT_HAND_KEYS THUMB_KEYS>;
            hold-trigger-on-release;
            tapping-term-ms = <RIGHT_PINKY_HOLDING_TIME>;
            quick-tap-ms = <RIGHT_PINKY_REPEAT_DECAY>;
            require-prior-idle-ms = <RIGHT_PINKY_STREAK_DECAY>;
            #binding-cells = <2>;
            bindings = <&kp>, <&kp>;
        };

        right_pinky_ringy_bilateral: homey_right_pinky_ringy_bilateral {
            compatible = "zmk,behavior-hold-tap";
            flavor = RIGHT_PINKY_HOLDING_TYPE;
            hold-trigger-key-positions = <LEFT_HAND_KEYS THUMB_KEYS>;
            hold-trigger-on-release;
            tapping-term-ms = <RIGHT_PINKY_HOLDING_TIME>;
            quick-tap-ms = <RIGHT_PINKY_REPEAT_DECAY>;
            require-prior-idle-ms = <RIGHT_PINKY_STREAK_DECAY>;
            #binding-cells = <2>;
            bindings = <&kp>, <&right_pinky_tap>;
        };

        #define RightPinkyRingy right_pinky_ringy_bilateral RIGHT_RINGY_MOD RIGHT_RINGY_KEY

        // Pinky + Middy chord
        right_pinky_middy: homey_right_pinky_middy {
            compatible = "zmk,behavior-hold-tap";
            flavor = RIGHT_PINKY_HOLDING_TYPE;
            hold-trigger-key-positions = <LEFT_HAND_KEYS THUMB_KEYS>;
            hold-trigger-on-release;
            tapping-term-ms = <RIGHT_PINKY_HOLDING_TIME>;
            quick-tap-ms = <RIGHT_PINKY_REPEAT_DECAY>;
            require-prior-idle-ms = <RIGHT_PINKY_STREAK_DECAY>;
            #binding-cells = <2>;
            bindings = <&kp>, <&kp>;
        };

        right_pinky_middy_bilateral: homey_right_pinky_middy_bilateral {
            compatible = "zmk,behavior-hold-tap";
            flavor = RIGHT_PINKY_HOLDING_TYPE;
            hold-trigger-key-positions = <LEFT_HAND_KEYS THUMB_KEYS>;
            hold-trigger-on-release;
            tapping-term-ms = <RIGHT_PINKY_HOLDING_TIME>;
            quick-tap-ms = <RIGHT_PINKY_REPEAT_DECAY>;
            require-prior-idle-ms = <RIGHT_PINKY_STREAK_DECAY>;
            #binding-cells = <2>;
            bindings = <&kp>, <&right_pinky_tap>;
        };

        #define RightPinkyMiddy right_pinky_middy_bilateral RIGHT_MIDDY_MOD RIGHT_MIDDY_KEY

        // Pinky + Index chord
        right_pinky_index: homey_right_pinky_index {
            compatible = "zmk,behavior-hold-tap";
            flavor = RIGHT_PINKY_HOLDING_TYPE;
            hold-trigger-key-positions = <LEFT_HAND_KEYS THUMB_KEYS>;
            hold-trigger-on-release;
            tapping-term-ms = <RIGHT_PINKY_HOLDING_TIME>;
            quick-tap-ms = <RIGHT_PINKY_REPEAT_DECAY>;
            require-prior-idle-ms = <RIGHT_PINKY_STREAK_DECAY>;
            #binding-cells = <2>;
            bindings = <&kp>, <&kp>;
        };

        right_pinky_index_bilateral: homey_right_pinky_index_bilateral {
            compatible = "zmk,behavior-hold-tap";
            flavor = RIGHT_PINKY_HOLDING_TYPE;
            hold-trigger-key-positions = <LEFT_HAND_KEYS THUMB_KEYS>;
            hold-trigger-on-release;
            tapping-term-ms = <RIGHT_PINKY_HOLDING_TIME>;
            quick-tap-ms = <RIGHT_PINKY_REPEAT_DECAY>;
            require-prior-idle-ms = <RIGHT_PINKY_STREAK_DECAY>;
            #binding-cells = <2>;
            bindings = <&kp>, <&right_pinky_tap>;
        };

        #define RightPinkyIndex right_pinky_index_bilateral RIGHT_INDEX_MOD RIGHT_INDEX_KEY

    };

    combos {
        compatible = "zmk,combos";

        // Q+W = ESC
        combo_esc {
            timeout-ms = <50>;
            key-positions = <0 1>;
            bindings = <&kp ESC>;
        };

        // C+V = Enter
        combo_enter {
            timeout-ms = <50>;
            key-positions = <23 24>;
            bindings = <&kp RET>;
        };

        // Q+DEL = Toggle to previous BT profile
        combo_bt_toggle_prev {
            timeout-ms = <50>;
            key-positions = <0 34>;
            bindings = <&bt BT_SEL 255>;
        };
    };

    keymap {
        compatible = "zmk,keymap";

        base_layer {
            label= "BASE";
            bindings = <
                          &kp Q                   &kp W                   &kp E                   &kp R                   &kp T                                                       &kp Y               &kp U                 &kp I                 &kp O                 &kp P
                          &LeftPinky(A, BASE)     &LeftRingy(S, BASE)     &LeftMiddy(D, BASE)     &LeftIndex(F, BASE)     &kp G                                                       &kp H               &RightIndex(J, BASE)  &RightMiddy(K, BASE)  &RightRingy(L, BASE)  &RightPinky(SEMI, BASE)
                &kp MINUS &kp Z                   &kp X                   &kp C                   &kp V                   &kp B                                                       &kp N               &kp M                 &kp COMMA             &kp DOT               &kp FSLH                &kp SQT
                                                                                                  &kp LEFT                &lt_space_sym SYM SPACE  &lt_del_nav NAV DEL    &lt_ret_nav NAV RET  &lt_bspc_sym SYM BSPC  &kp RIGHT
            >;
        };

        nav_layer {
            label= "NAVI";
            bindings = <
                                &none           &none           &kp UP          &none           &kp _CUT                                             &kp KP_NUM      &kp KP_N7       &kp KP_N8       &kp KP_N9       &kp KP_PLUS
                                &none           &kp LEFT        &kp DOWN        &kp RIGHT       &kp _COPY                                            &kp INSERT      &kp KP_N4       &kp KP_N5       &kp KP_N6       &kp KP_MINUS
                &none           &none           &none           &none           &none           &kp _PASTE                                           &kp SLCK        &kp KP_N1       &kp KP_N2       &kp KP_N3       &kp KP_MULTIPLY &kp KP_DIVIDE
                                                                                &trans          &trans          &trans               &mo ADJ         &kp KP_EQUAL    &kp KP_N0
            >;
        };

        sim_layer {
            label= "SYM";
            bindings = <
                                &kp N1          &kp N2          &kp N3          &kp N4          &kp N5                                              &kp N6          &kp N7        &kp N8          &kp N9          &kp N0
                                &kp LCTRL       &kp BSLH        &kp SQT         &kp LSHFT       &parang_left                                        &kp PG_UP       &kp RSHFT     &kp EQUAL       &kp MINUS       &kp GRAVE
                &kp TAB         &kp HOME        &kp END         &kp LEFT        &kp RIGHT       &parang_right                                       &kp PG_DN       &kp UP        &kp DOWN        &kp LBKT        &kp RBKT        &euro_symbol
                                                                                &kp CAPS        &trans          &mo ADJ             &mo ADJ         &trans          &kp CAPS
            >;
        };

        adjust_layer {
            label= "ADJ";
            bindings = <
                &sys_reset      &bt BT_CLR      &out OUT_TOG    &bt BT_SEL 0    &bt BT_SEL 3        &trans          &kp F7          &kp F8          &kp F9          &kp F12
                &bootloader     &bt BT_NXT      &trans          &bt BT_SEL 1    &bt BT_SEL 4        &trans          &kp F4          &kp F5          &kp F6          &kp F11
                &trans          &trans          &bt BT_PRV      &trans          &bt BT_SEL 2    &trans              &trans          &kp F1          &kp F2          &kp F3          &kp F10         &trans
                                                                &trans          &trans          &trans              &trans          &trans          &trans
            >;
        };

        // Finger layers - activate modifier while tapping keys on same hand
        layer_LeftPinky {
            label= "LPinky";
            bindings = <
                &left_pinky_tap Q  &left_pinky_tap W  &left_pinky_tap E  &left_pinky_tap R  &left_pinky_tap T      &trans  &trans  &trans  &trans  &trans
                &none              &LeftPinkyRingy    &LeftPinkyMiddy    &LeftPinkyIndex    &left_pinky_tap G      &trans  &kp J   &kp K   &kp L   &kp SEMI
                &trans             &left_pinky_tap Z  &left_pinky_tap X  &left_pinky_tap C  &left_pinky_tap V  &left_pinky_tap B      &trans  &trans  &trans  &trans  &trans  &trans
                                                                          &trans             &trans             &trans                 &trans  &trans  &trans
            >;
        };

        layer_LeftRingy {
            label= "LRingy";
            bindings = <
                &left_ringy_tap Q  &left_ringy_tap W  &left_ringy_tap E  &left_ringy_tap R  &left_ringy_tap T      &trans  &trans  &trans  &trans  &trans
                &LeftRingyPinky    &none              &LeftRingyMiddy    &LeftRingyIndex    &left_ringy_tap G      &trans  &kp J   &kp K   &kp L   &kp SEMI
                &trans             &left_ringy_tap Z  &left_ringy_tap X  &left_ringy_tap C  &left_ringy_tap V  &left_ringy_tap B      &trans  &trans  &trans  &trans  &trans  &trans
                                                                          &trans             &trans             &trans                 &trans  &trans  &trans
            >;
        };

        layer_LeftMiddy {
            label= "LMiddy";
            bindings = <
                &left_middy_tap Q  &left_middy_tap W  &left_middy_tap E  &left_middy_tap R  &left_middy_tap T      &trans  &trans  &trans  &trans  &trans
                &LeftMiddyPinky    &LeftMiddyRingy    &none              &LeftMiddyIndex    &left_middy_tap G      &trans  &kp J   &kp K   &kp L   &kp SEMI
                &trans             &left_middy_tap Z  &left_middy_tap X  &left_middy_tap C  &left_middy_tap V  &left_middy_tap B      &trans  &trans  &trans  &trans  &trans  &trans
                                                                          &trans             &trans             &trans                 &trans  &trans  &trans
            >;
        };

        layer_LeftIndex {
            label= "LIndex";
            bindings = <
                &left_index_tap Q  &left_index_tap W  &left_index_tap E  &left_index_tap R  &left_index_tap T      &trans  &trans  &trans  &trans  &trans
                &LeftIndexPinky    &LeftIndexRingy    &LeftIndexMiddy    &none              &left_index_tap G      &trans  &kp J   &kp K   &kp L   &kp SEMI
                &trans             &left_index_tap Z  &left_index_tap X  &left_index_tap C  &left_index_tap V  &left_index_tap B      &trans  &trans  &trans  &trans  &trans  &trans
                                                                          &trans             &trans             &trans                 &trans  &trans  &trans
            >;
        };

        layer_RightPinky {
            label= "RPinky";
            bindings = <
                &trans  &trans  &trans  &trans  &trans      &right_pinky_tap Y  &right_pinky_tap U  &right_pinky_tap I  &right_pinky_tap O  &right_pinky_tap P
                &kp A   &kp S   &kp D   &kp F   &trans      &right_pinky_tap H  &RightPinkyIndex    &RightPinkyMiddy    &RightPinkyRingy    &none
                &trans  &trans  &trans  &trans  &trans  &trans      &right_pinky_tap N  &right_pinky_tap M  &right_pinky_tap COMMA  &right_pinky_tap DOT  &right_pinky_tap FSLH  &trans
                                        &trans  &trans  &trans      &trans              &trans              &trans
            >;
        };

        layer_RightRingy {
            label= "RRingy";
            bindings = <
                &trans  &trans  &trans  &trans  &trans      &right_ringy_tap Y  &right_ringy_tap U  &right_ringy_tap I  &right_ringy_tap O  &right_ringy_tap P
                &kp A   &kp S   &kp D   &kp F   &trans      &right_ringy_tap H  &RightRingyIndex    &RightRingyMiddy    &none               &RightRingyPinky
                &trans  &trans  &trans  &trans  &trans  &trans      &right_ringy_tap N  &right_ringy_tap M  &right_ringy_tap COMMA  &right_ringy_tap DOT  &right_ringy_tap FSLH  &trans
                                        &trans  &trans  &trans      &trans              &trans              &trans
            >;
        };

        layer_RightMiddy {
            label= "RMiddy";
            bindings = <
                &trans  &trans  &trans  &trans  &trans      &right_middy_tap Y  &right_middy_tap U  &right_middy_tap I  &right_middy_tap O  &right_middy_tap P
                &kp A   &kp S   &kp D   &kp F   &trans      &right_middy_tap H  &RightMiddyIndex    &none               &RightMiddyRingy    &RightMiddyPinky
                &trans  &trans  &trans  &trans  &trans  &trans      &right_middy_tap N  &right_middy_tap M  &right_middy_tap COMMA  &right_middy_tap DOT  &right_middy_tap FSLH  &trans
                                        &trans  &trans  &trans      &trans              &trans              &trans
            >;
        };

        layer_RightIndex {
            label= "RIndex";
            bindings = <
                &trans  &trans  &trans  &trans  &trans      &right_index_tap Y  &right_index_tap U  &right_index_tap I  &right_index_tap O  &right_index_tap P
                &kp A   &kp S   &kp D   &kp F   &trans      &right_index_tap H  &none               &RightIndexMiddy    &RightIndexRingy    &RightIndexPinky
                &trans  &trans  &trans  &trans  &trans  &trans      &right_index_tap N  &right_index_tap M  &right_index_tap COMMA  &right_index_tap DOT  &right_index_tap FSLH  &trans
                                        &trans  &trans  &trans      &trans              &trans              &trans
            >;
        };
    };
};
